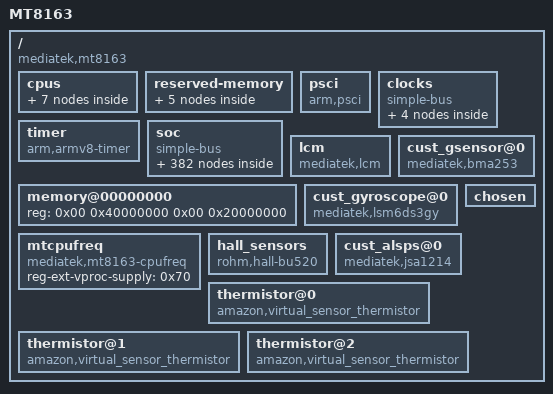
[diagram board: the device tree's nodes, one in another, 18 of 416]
/dts-v1/;

/ {
	model = "MT8163";
	compatible = "mediatek,mt8163";
	interrupt-parent = <0x01>;
	#address-cells = <0x02>;
	#size-cells = <0x02>;
	version = "hvt";

	cpus {
		#address-cells = <0x01>;
		#size-cells = <0x00>;

		cpu@0 {
			device_type = "cpu";
			compatible = "arm,cortex-a53";
			reg = <0x00>;
			enable-method = "mt-boot";
			cpu-idle-states = <0x02 0x02 0x03 0x03 0x03>;
			cpu-release-addr = <0x00 0x40000200>;
			clock-frequency = "M|m";
		};

		cpu@1 {
			device_type = "cpu";
			compatible = "arm,cortex-a53";
			reg = <0x01>;
			enable-method = "mt-boot";
			cpu-idle-states = <0x02 0x02 0x03 0x03 0x03>;
			cpu-release-addr = <0x00 0x40000200>;
			clock-frequency = "M|m";
		};

		cpu@2 {
			device_type = "cpu";
			compatible = "arm,cortex-a53";
			reg = <0x02>;
			enable-method = "mt-boot";
			cpu-idle-states = <0x02 0x02 0x03 0x03 0x03>;
			cpu-release-addr = <0x00 0x40000200>;
			clock-frequency = "M|m";
		};

		cpu@3 {
			device_type = "cpu";
			compatible = "arm,cortex-a53";
			reg = <0x03>;
			enable-method = "mt-boot";
			cpu-idle-states = <0x02 0x02 0x03 0x03 0x03>;
			cpu-release-addr = <0x00 0x40000200>;
			clock-frequency = "M|m";
		};

		idle-states {
			entry-method = "arm,psci";

			cpu-sleep-0-0 {
				compatible = "arm,idle-state";
				arm,psci-suspend-param = <0x10000>;
				entry-latency-us = <0x258>;
				exit-latency-us = <0x258>;
				min-residency-us = <0x4b0>;
				linux,phandle = <0x03>;
				phandle = <0x03>;
			};

			cluster-sleep-0 {
				compatible = "arm,idle-state";
				arm,psci-suspend-param = <0x2010000>;
				entry-latency-us = <0x320>;
				exit-latency-us = <0x3e8>;
				min-residency-us = <0x7d0>;
				linux,phandle = <0x02>;
				phandle = <0x02>;
			};
		};
	};

	reserved-memory {
		#address-cells = <0x02>;
		#size-cells = <0x02>;
		ranges;

		mdump-reserved-memory@4bd00000 {
			compatible = "amazon,mdump-reserve-memory";
			reg = <0x00 0x4bd00000 0x00 0x300000>;
		};

		atf-reserved-memory@43000000 {
			compatible = "mediatek,mt8163-atf-reserved-memory";
			no-map;
			reg = <0x00 0x43000000 0x00 0x30000>;
		};

		ram_console-reserved-memory@44400000 {
			compatible = "mediatek,ram_console";
			reg = <0x00 0x44400000 0x00 0x200000>;
		};

		consys-reserve-memory {
			compatible = "mediatek,consys-reserve-memory";
			no-map;
			size = <0x00 0x200000>;
			alignment = <0x00 0x200000>;
		};

		ll_log-reserved-memory@46600000 {
			compatible = "amazon,ll_log-reserved-memory";
			reg = <0x00 0x44600000 0x00 0x20000>;
		};
	};

	psci {
		compatible = "arm,psci";
		method = "smc";
		cpu_suspend = <0x84000001>;
		cpu_off = <0x84000002>;
		cpu_on = <0x84000003>;
		affinity_info = <0x84000004>;
	};

	clocks {
		#address-cells = <0x02>;
		#size-cells = <0x02>;
		compatible = "simple-bus";
		ranges;

		clk_null {
			compatible = "fixed-clock";
			#clock-cells = <0x00>;
			clock-frequency = <0x00>;
			linux,phandle = <0x3e>;
			phandle = <0x3e>;
		};

		clk26m {
			compatible = "fixed-clock";
			#clock-cells = <0x00>;
			clock-frequency = <0x18cba80>;
			linux,phandle = <0x33>;
			phandle = <0x33>;
		};

		clk32k {
			compatible = "fixed-clock";
			#clock-cells = <0x00>;
			clock-frequency = <0x7d00>;
		};

		dummy26m {
			compatible = "fixed-clock";
			clock-frequency = <0x18cba80>;
			#clock-cells = <0x00>;
		};
	};

	timer {
		compatible = "arm,armv8-timer";
		interrupt-parent = <0x04>;
		interrupts = <0x01 0x0d 0xf08 0x01 0x0e 0xf08 0x01 0x0b 0xf08 0x01 0x0a 0xf08>;
		clock-frequency = <0xc65d40>;
	};

	soc {
		#address-cells = <0x02>;
		#size-cells = <0x02>;
		compatible = "simple-bus";
		ranges;

		chipid@08000000 {
			compatible = "mediatek,mt8163-chipid";
			reg = <0x00 0x8000000 0x00 0x10>;
		};

		topckgen@10000000 {
			compatible = "mediatek,mt8163-topckgen";
			reg = <0x00 0x10000000 0x00 0x1000>;
			#clock-cells = <0x01>;
			linux,phandle = <0x06>;
			phandle = <0x06>;
		};

		infracfg@10001000 {
			compatible = "mediatek,mt8163-infracfg\0syscon";
			reg = <0x00 0x10001000 0x00 0x1000>;
			#clock-cells = <0x01>;
			#reset-cells = <0x01>;
			linux,phandle = <0x05>;
			phandle = <0x05>;
		};

		syscfg_pctl_a@10005000 {
			compatible = "mediatek,mt8163-pctl-a-syscfg\0syscon";
			reg = <0x00 0x10005000 0x00 0x1000>;
			linux,phandle = <0x07>;
			phandle = <0x07>;
		};

		toprgu@10007000 {
			compatible = "mediatek,mt8163-rgu";
			reg = <0x00 0x10007000 0x00 0x1000>;
			interrupts = <0x00 0x80 0x02>;
			#reset-cells = <0x01>;
		};

		apxgpt@10008000 {
			compatible = "mediatek,mt8163-apxgpt";
			reg = <0x00 0x10008000 0x00 0x1000>;
			interrupts = <0x00 0x98 0x08>;
			clocks = <0x05 0x06 0x05 0x46 0x06 0x60>;
			clock-names = "bus\0clk13m\0rtc_sel";
		};

		pinctrl@10005000 {
			compatible = "mediatek,mt8163-pinctrl";
			reg = <0x00 0x1000b000 0x00 0x1000>;
			mediatek,pctl-regmap = <0x07>;
			pins-are-numbered;
			gpio-controller;
			#gpio-cells = <0x02>;
			interrupt-controller;
			#interrupt-cells = <0x02>;
			interrupts = <0x00 0x99 0x04 0x00 0x9a 0x04 0x00 0x9b 0x04>;
			pinctrl-names = "default";
			pinctrl-0 = <0x08>;
			linux,phandle = <0x09>;
			phandle = <0x09>;

			spi1 {
				linux,phandle = <0x27>;
				phandle = <0x27>;

				pins_spi {
					pinmux = <0x3501 0x3601 0x3701 0x3801>;
					bias-disable;
					drive-strength = <0x08>;
				};
			};

			uart0gpiodefault {
				linux,phandle = <0x0b>;
				phandle = <0x0b>;
			};

			uart0_rx_set {
				linux,phandle = <0x0c>;
				phandle = <0x0c>;

				pins_cmd_dat {
					pinmux = <0x4f01>;
				};
			};

			uart0_rx_clear {
				linux,phandle = <0x0d>;
				phandle = <0x0d>;

				pins_cmd_dat {
					pinmux = <0x4f00>;
					slew-rate = <0x01>;
					output-high;
				};
			};

			uart0_tx_set {
				linux,phandle = <0x0e>;
				phandle = <0x0e>;

				pins_cmd_dat {
					pinmux = <0x5001>;
				};
			};

			uart0_tx_clear {
				linux,phandle = <0x0f>;
				phandle = <0x0f>;

				pins_cmd_dat {
					pinmux = <0x5000>;
					slew-rate = <0x01>;
					output-high;
				};
			};

			uart1gpiodefault {
				linux,phandle = <0x10>;
				phandle = <0x10>;
			};

			uart1_rx_set {
				linux,phandle = <0x11>;
				phandle = <0x11>;

				pins_cmd_dat {
					pinmux = <0x5101>;
				};
			};

			uart1_rx_clear {
				linux,phandle = <0x12>;
				phandle = <0x12>;

				pins_cmd_dat {
					pinmux = <0x5100>;
					slew-rate = <0x01>;
					output-high;
				};
			};

			uart1_tx_set {
				linux,phandle = <0x13>;
				phandle = <0x13>;

				pins_cmd_dat {
					pinmux = <0x5201>;
				};
			};

			uart1_tx_clear {
				linux,phandle = <0x14>;
				phandle = <0x14>;

				pins_cmd_dat {
					pinmux = <0x5200>;
					slew-rate = <0x01>;
					output-high;
				};
			};

			uart2gpiodefault {
				linux,phandle = <0x15>;
				phandle = <0x15>;
			};

			uart2_rx_set {
				linux,phandle = <0x16>;
				phandle = <0x16>;

				pins_cmd_dat {
					pinmux = <0xe01>;
				};
			};

			uart2_rx_clear {
				linux,phandle = <0x17>;
				phandle = <0x17>;

				pins_cmd_dat {
					pinmux = <0xe00>;
					slew-rate = <0x01>;
					output-high;
				};
			};

			uart2_tx_set {
				linux,phandle = <0x18>;
				phandle = <0x18>;

				pins_cmd_dat {
					pins = <0xf01>;
				};
			};

			uart2_tx_clear {
				linux,phandle = <0x19>;
				phandle = <0x19>;

				pins_cmd_dat {
					pinmux = <0xf00>;
					slew-rate = <0x01>;
					output-high;
				};
			};

			uart3gpiodefault {
				linux,phandle = <0x1a>;
				phandle = <0x1a>;
			};

			uart3_rx_set {
				linux,phandle = <0x1b>;
				phandle = <0x1b>;

				pins_cmd_dat {
					pinmux = <0x1001>;
				};
			};

			uart3_rx_clear {
				linux,phandle = <0x1c>;
				phandle = <0x1c>;

				pins_cmd_dat {
					pinmux = <0x1000>;
					slew-rate = <0x01>;
					output-high;
				};
			};

			uart3_tx_set {
				linux,phandle = <0x1d>;
				phandle = <0x1d>;

				pins_cmd_dat {
					pinmux = <0x1101>;
				};
			};

			uart3_tx_clear {
				linux,phandle = <0x1e>;
				phandle = <0x1e>;

				pins_cmd_dat {
					pinmux = <0x1100>;
					slew-rate = <0x01>;
					output-high;
				};
			};

			pinconf_default {
				linux,phandle = <0x08>;
				phandle = <0x08>;
			};

			eint4default {
				linux,phandle = <0x60>;
				phandle = <0x60>;
			};

			eint4 {
				linux,phandle = <0x61>;
				phandle = <0x61>;

				pins_cmd_dat {
					pins = <0x1a00>;
					input-enable;
					bias-pull-down;
				};
			};

			bq24297_int_pin {
				linux,phandle = <0x26>;
				phandle = <0x26>;

				pins_cmd_dat {
					pinmux = <0x1700>;
					input-enable;
					bias-pull-up;
				};
			};

			bq24297_chg_en_pin {
				linux,phandle = <0x25>;
				phandle = <0x25>;

				pins_cmd_dat {
					pins = <0x1600>;
					slew-rate = <0x01>;
					bias-disable;
					output-low;
				};
			};

			alspspincfg {
				linux,phandle = <0x6a>;
				phandle = <0x6a>;

				pins_cmd_dat {
					pins = <0x3400>;
					slew-rate = <0x00>;
					bias-pull-up = <0x00>;
				};
			};

			alspsdefaultcfg {
				linux,phandle = <0x69>;
				phandle = <0x69>;
			};

			audiodefault {
				linux,phandle = <0x35>;
				phandle = <0x35>;
			};

			audexamphigh {
				linux,phandle = <0x3a>;
				phandle = <0x3a>;

				pins_cmd_dat {
					pins = <0x1c00>;
					slew-rate = <0x01>;
					output-high;
				};
			};

			audexamplow {
				linux,phandle = <0x3b>;
				phandle = <0x3b>;

				pins_cmd_dat {
					pins = <0x1c00>;
					slew-rate = <0x01>;
					output-low;
				};
			};

			audhpamphigh {
				linux,phandle = <0x3c>;
				phandle = <0x3c>;

				pins_cmd_dat {
					pins = <0x2c00>;
					slew-rate = <0x01>;
					output-high;
				};
			};

			audhpamplow {
				linux,phandle = <0x3d>;
				phandle = <0x3d>;

				pins_cmd_dat {
					pins = <0x2c00>;
					slew-rate = <0x01>;
					output-low;
				};
			};

			audFSA8409off {
				linux,phandle = <0x62>;
				phandle = <0x62>;

				pins_cmd_dat {
					pins = <0x1b00>;
					slew-rate = <0x01>;
					output-low;
				};
			};

			audFSA8409on {
				linux,phandle = <0x63>;
				phandle = <0x63>;

				pins_cmd_dat {
					pins = <0x1b00>;
					slew-rate = <0x01>;
					output-high;
				};
			};

			audi2s1mode0 {
				linux,phandle = <0x38>;
				phandle = <0x38>;

				pins_cmd0_dat {
					pins = <0x2e00>;
				};

				pins_cmd1_dat {
					pins = <0x2f00>;
				};

				pins_cmd2_dat {
					pins = <0x3000>;
				};
			};

			audi2s1mode1 {
				linux,phandle = <0x39>;
				phandle = <0x39>;

				pins_cmd0_dat {
					pins = <0x2e02>;
				};

				pins_cmd1_dat {
					pins = <0x2f02>;
				};

				pins_cmd2_dat {
					pins = <0x3002>;
				};
			};

			pmicclkmode0 {
				linux,phandle = <0x36>;
				phandle = <0x36>;

				pins_cmd0_dat {
					pins = <0x700>;
				};

				pins_cmd1_dat {
					pins = <0x800>;
				};

				pins_cmd2_dat {
					pins = <0x900>;
				};
			};

			pmicclkmode1 {
				linux,phandle = <0x37>;
				phandle = <0x37>;

				pins_cmd0_dat {
					pins = <0x701>;
				};

				pins_cmd1_dat {
					pins = <0x801>;
				};

				pins_cmd2_dat {
					pins = <0x901>;
				};
			};

			cam0@0 {
				linux,phandle = <0x4d>;
				phandle = <0x4d>;

				pins_cmd_dat {
					pins = <0x3500>;
					slew-rate = <0x01>;
					output-low;
				};
			};

			cam0@1 {
				linux,phandle = <0x4e>;
				phandle = <0x4e>;

				pins_cmd_dat {
					pins = <0x3500>;
					slew-rate = <0x01>;
					output-high;
				};
			};

			cam0@2 {
				linux,phandle = <0x4f>;
				phandle = <0x4f>;

				pins_cmd_dat {
					pins = <0x3800>;
					slew-rate = <0x01>;
					output-low;
				};
			};

			cam0@3 {
				linux,phandle = <0x50>;
				phandle = <0x50>;

				pins_cmd_dat {
					pins = <0x3800>;
					slew-rate = <0x01>;
					output-high;
				};
			};

			cam1@0 {
				linux,phandle = <0x51>;
				phandle = <0x51>;

				pins_cmd_dat {
					pins = <0x3700>;
					slew-rate = <0x01>;
					output-low;
				};
			};

			cam1@1 {
				linux,phandle = <0x52>;
				phandle = <0x52>;

				pins_cmd_dat {
					pins = <0x3700>;
					slew-rate = <0x01>;
					output-high;
				};
			};

			cam1@2 {
				linux,phandle = <0x53>;
				phandle = <0x53>;

				pins_cmd_dat {
					pins = <0x3600>;
					slew-rate = <0x01>;
					output-low;
				};
			};

			cam1@3 {
				linux,phandle = <0x54>;
				phandle = <0x54>;

				pins_cmd_dat {
					pins = <0x3600>;
					slew-rate = <0x01>;
					output-high;
				};
			};

			camdefault {
				linux,phandle = <0x4c>;
				phandle = <0x4c>;

				pins_cmd0_dat {
					pins = <0x7701>;
				};

				pins_cmd1_dat {
					pins = <0x6b02>;
				};

				pins_cmd2_dat {
					pins = <0x6c02>;
				};

				pins_cmd3_dat {
					pins = <0x6d02>;
				};

				pins_cmd4_dat {
					pins = <0x6e02>;
				};

				pins_cmd5_dat {
					pins = <0x6f02>;
				};

				pins_cmd6_dat {
					pins = <0x7002>;
				};

				pins_cmd7_dat {
					pins = <0x7102>;
				};

				pins_cmd8_dat {
					pins = <0x7202>;
				};

				pins_cmd9_dat {
					pins = <0x7302>;
				};

				pins_cmd10_dat {
					pins = <0x7402>;
				};

				pins_cmd11_dat {
					pins = <0x7801>;
				};
			};

			default {
				linux,phandle = <0x57>;
				phandle = <0x57>;
			};

			eint0default {
				linux,phandle = <0x65>;
				phandle = <0x65>;

				pins_cmd_dat {
					pins = <0x2300>;
					slew-rate = <0x00>;
					bias-disable;
				};
			};

			eint@0 {
				linux,phandle = <0x22>;
				phandle = <0x22>;

				pins_cmd_dat {
					pins = <0x2300>;
					slew-rate = <0x00>;
					bias-disable;
				};
			};

			eintoutput0 {
				linux,phandle = <0x21>;
				phandle = <0x21>;

				pins_cmd_dat {
					pins = <0x2300>;
					slew-rate = <0x01>;
					output-low;
				};
			};

			eintoutput1 {
				linux,phandle = <0x66>;
				phandle = <0x66>;

				pins_cmd_dat {
					pins = <0x2300>;
					slew-rate = <0x01>;
					output-high;
				};
			};

			rstoutput0 {
				linux,phandle = <0x67>;
				phandle = <0x67>;

				pins_cmd_dat {
					pins = <0x2e00>;
					slew-rate = <0x01>;
					output-low;
				};
			};

			rstoutput1 {
				linux,phandle = <0x68>;
				phandle = <0x68>;

				pins_cmd_dat {
					pins = <0x2e00>;
					slew-rate = <0x01>;
					output-high;
				};
			};

			iddig_irq_init {
				linux,phandle = <0x2a>;
				phandle = <0x2a>;

				pins_cmd_dat {
					pins = <0x2600>;
					bias-pull-up;
				};
			};

			iddig_irq_low {
				linux,phandle = <0x2b>;
				phandle = <0x2b>;

				pins_cmd_dat {
					pins = <0x2600>;
					bias-pull-down;
				};
			};

			iddig_irq_high {
				linux,phandle = <0x2c>;
				phandle = <0x2c>;

				pins_cmd_dat {
					pins = <0x2600>;
					bias-pull-up;
				};
			};

			drvvbus_init {
				linux,phandle = <0x2d>;
				phandle = <0x2d>;

				pins_cmd_dat {
					pins = <0x1e00>;
					slew-rate = <0x01>;
					bias-pull-up = <0x00>;
				};
			};

			drvvbus_low {
				linux,phandle = <0x2e>;
				phandle = <0x2e>;

				pins_cmd_dat {
					pins = <0x1e00>;
					slew-rate = <0x01>;
					output-low;
				};
			};

			drvvbus_high {
				linux,phandle = <0x2f>;
				phandle = <0x2f>;

				pins_cmd_dat {
					pins = <0x1e00>;
					slew-rate = <0x01>;
					output-high;
				};
			};

			otg5ven_init {
				linux,phandle = <0x30>;
				phandle = <0x30>;

				pins_cmd_dat {
					pins = <0x1d00>;
					slew-rate = <0x01>;
					bias-pull-up = <0x00>;
				};
			};

			otg5ven_low {
				linux,phandle = <0x31>;
				phandle = <0x31>;

				pins_cmd_dat {
					pins = <0x1d00>;
					slew-rate = <0x01>;
					output-low;
				};
			};

			otg5ven_high {
				linux,phandle = <0x32>;
				phandle = <0x32>;

				pins_cmd_dat {
					pins = <0x1d00>;
					slew-rate = <0x01>;
					output-high;
				};
			};

			gpslna@0 {
				linux,phandle = <0x58>;
				phandle = <0x58>;

				pins_cmd_dat {
					pinmux = <0x600>;
					slew-rate = <0x00>;
					bias-disable;
					output-low;
				};
			};

			gpslna@1 {
				linux,phandle = <0x59>;
				phandle = <0x59>;

				pins_cmd_dat {
					pinmux = <0x600>;
					slew-rate = <0x01>;
					output-high;
				};
			};

			gpslna@2 {
				linux,phandle = <0x5a>;
				phandle = <0x5a>;

				pins_cmd_dat {
					pinmux = <0x600>;
					slew-rate = <0x01>;
					output-low;
				};
			};

			wifireset@0 {
				linux,phandle = <0x5b>;
				phandle = <0x5b>;

				pins_reset_dat {
					pinmux = <0x3c01 0x3f01 0x4001 0x4101>;
					input-enable;
					bias-pull-up;
				};
			};

			i2c0@0 {
				linux,phandle = <0x1f>;
				phandle = <0x1f>;

				pins1 {
					pinmux = <0x4b01 0x4c01>;
					bias-disable;
				};
			};

			i2c1@0 {
				linux,phandle = <0x23>;
				phandle = <0x23>;

				pins1 {
					pinmux = <0x3901 0x3a01>;
					bias-disable;
				};
			};

			i2c2@0 {
				linux,phandle = <0x24>;
				phandle = <0x24>;

				pins1 {
					pinmux = <0x4d01 0x4e01>;
					bias-disable;
				};
			};

			lcm_gpio@43_high {
				linux,phandle = <0x6b>;
				phandle = <0x6b>;

				pins_cmd_dat {
					pins = <0x2b00>;
					slew-rate = <0x01>;
					output-high;
				};
			};

			lcm_gpio@43_low {
				linux,phandle = <0x6c>;
				phandle = <0x6c>;

				pins_cmd_dat {
					pins = <0x2b00>;
					slew-rate = <0x01>;
					output-low;
				};
			};

			lcm_gpio@83_high {
				linux,phandle = <0x6d>;
				phandle = <0x6d>;

				pins_cmd_dat {
					pins = <0x5300>;
					slew-rate = <0x01>;
					output-high;
				};
			};

			lcm_gpio@83_low {
				linux,phandle = <0x6e>;
				phandle = <0x6e>;

				pins_cmd_dat {
					pins = <0x5300>;
					slew-rate = <0x01>;
					output-low;
				};
			};

			mmc0default {
				linux,phandle = <0x3f>;
				phandle = <0x3f>;

				pins_cmd_dat {
					pinmux = <0x8901 0x8801 0x8701 0x8601 0x8201 0x8101 0x8001 0x7f01 0x8401>;
					input-enable;
					bias-pull-up;
				};

				pins_clk {
					pinmux = <0x8501>;
					bias-pull-down;
				};

				pins_rst {
					pinmux = <0x8301>;
					bias-pull-up;
				};
			};

			mmc0@0 {
				linux,phandle = <0x40>;
				phandle = <0x40>;

				pins_cmd_dat {
					pinmux = <0x8901 0x8801 0x8701 0x8601 0x8201 0x8101 0x8001 0x7f01 0x8401>;
					input-enable;
					drive-strength = <0x06>;
					bias-pull-up = <0x65>;
				};

				pins_clk {
					pinmux = <0x8501>;
					drive-strength = <0x06>;
					bias-pull-down = <0x65>;
				};

				pins_rst {
					pinmux = <0x8301>;
					bias-pull-up;
				};
			};

			mmc1default {
				linux,phandle = <0x43>;
				phandle = <0x43>;

				pins_cmd_dat {
					pinmux = <0x7b01 0x7c01 0x7d01 0x7e01 0x7901>;
					input-enable;
					drive-strength = <0x06>;
					bias-pull-up = <0x65>;
				};

				pins_clk {
					pinmux = <0x7a01>;
					bias-pull-down = <0x66>;
					drive-strength = <0x06>;
				};

				pins_insert {
					pinmux = <0x3100>;
					bias-pull-up;
				};
			};

			mmc1@0 {
				linux,phandle = <0x44>;
				phandle = <0x44>;

				pins_cmd_dat {
					pinmux = <0x7b01 0x7c01 0x7d01 0x7e01 0x7901>;
					input-enable;
					drive-strength = <0x08>;
					bias-pull-up = <0x66>;
				};

				pins_clk {
					pinmux = <0x7a01>;
					drive-strength = <0x08>;
					bias-pull-down = <0x66>;
				};
			};
		};

		dramco@10004000 {
			compatible = "mediatek,mt8163-dramco\0mediatek,dramco";
			reg = <0x00 0x10004000 0x00 0x1000>;
		};

		scpsys@10006000 {
			compatible = "mediatek,mt8163-scpsys\0syscon";
			#power-domain-cells = <0x01>;
			reg = <0x00 0x10006000 0x00 0x1000>;
			interrupts = <0x00 0xa3 0x08 0x00 0xa4 0x08 0x00 0xa5 0x08 0x00 0xa6 0x08 0x00 0xa7 0x08 0x00 0xa8 0x08 0x00 0xa9 0x08 0x00 0xaa 0x08>;
			infracfg = <0x05>;
			clocks = <0x06 0x46 0x06 0x43>;
			clock-names = "mfg\0mm";
			linux,phandle = <0x34>;
			phandle = <0x34>;
		};

		hacc@1000a000 {
			compatible = "mediatek,hacc";
			reg = <0x00 0x1000a000 0x00 0x1000>;
			clocks = <0x05 0x05>;
			clock-names = "main";
		};

		apmixedsys@1000c000 {
			compatible = "mediatek,mt8163-apmixedsys";
			reg = <0x00 0x1000c000 0x00 0x1000>;
			#clock-cells = <0x01>;
			linux,phandle = <0x28>;
			phandle = <0x28>;
		};

		fhctl@1000cf00 {
			compatible = "mediatek,mt8163-fhctl";
			reg = <0x00 0x1000cf00 0x00 0x100>;
		};

		pwrap@1000d000 {
			compatible = "mediatek,mt8163-pwrap";
			reg = <0x00 0x1000d000 0x00 0x1000>;
			reg-names = "pwrap-base";
			interrupts = <0x00 0xa1 0x04>;
			clocks = <0x06 0x51 0x05 0x01>;
			clock-names = "spi\0pwrap";

			mt6323 {
				compatible = "mediatek,mt6323";

				pmicmt6323 {
					compatible = "mediatek,mt6323-pmic";
					interrupt-parent = <0x09>;
					interrupts = <0x18 0x04>;
					log-dump-wait-time = <0x1770>;
				};

				regulators {
					compatible = "mediatek,mt6323-regulator";

					buck_vproc {
						regulator-name = "vproc";
						regulator-min-microvolt = <0xaae60>;
						regulator-max-microvolt = <0x149970>;
						regulator-ramp-delay = <0x30d4>;
						regulator-always-on;
						regulator-boot-on;
					};

					buck_vsys {
						regulator-name = "vsys";
						regulator-min-microvolt = <0x155cc0>;
						regulator-max-microvolt = <0x2d95ec>;
						regulator-ramp-delay = <0x61a8>;
						regulator-always-on;
						regulator-boot-on;
					};

					buck_vpa {
						regulator-name = "vpa";
						regulator-min-microvolt = <0x7a120>;
						regulator-max-microvolt = <0x37b1d0>;
					};

					ldo_vtcxo {
						regulator-name = "vtcxo";
						regulator-min-microvolt = <0x2ab980>;
						regulator-max-microvolt = <0x2ab980>;
						regulator-enable-ramp-delay = <0x5a>;
						regulator-always-on;
						regulator-boot-on;
					};

					ldo_vcn28 {
						regulator-name = "vcn28";
						regulator-min-microvolt = <0x2ab980>;
						regulator-max-microvolt = <0x2ab980>;
						regulator-enable-ramp-delay = <0xb9>;
						linux,phandle = <0x5d>;
						phandle = <0x5d>;
					};

					ldo_vcn33_bt {
						regulator-name = "vcn33_bt";
						regulator-min-microvolt = <0x325aa0>;
						regulator-max-microvolt = <0x36ee80>;
						regulator-enable-ramp-delay = <0xb9>;
						linux,phandle = <0x5e>;
						phandle = <0x5e>;
					};

					ldo_vcn33_wifi {
						regulator-name = "vcn33_wifi";
						regulator-min-microvolt = <0x325aa0>;
						regulator-max-microvolt = <0x36ee80>;
						regulator-enable-ramp-delay = <0xb9>;
						linux,phandle = <0x5f>;
						phandle = <0x5f>;
					};

					ldo_va {
						regulator-name = "va";
						regulator-min-microvolt = <0x2ab980>;
						regulator-max-microvolt = <0x2ab980>;
						regulator-enable-ramp-delay = <0xd8>;
						regulator-always-on;
						regulator-boot-on;
					};

					ldo_vcama {
						regulator-name = "vcama";
						regulator-min-microvolt = <0x16e360>;
						regulator-max-microvolt = <0x2ab980>;
						regulator-enable-ramp-delay = <0xd8>;
						linux,phandle = <0x49>;
						phandle = <0x49>;
					};

					ldo_vio28 {
						regulator-name = "vio28";
						regulator-min-microvolt = <0x2ab980>;
						regulator-max-microvolt = <0x2ab980>;
						regulator-enable-ramp-delay = <0xd8>;
						regulator-always-on;
						regulator-boot-on;
					};

					ldo_vusb {
						regulator-name = "vusb";
						regulator-min-microvolt = <0x325aa0>;
						regulator-max-microvolt = <0x325aa0>;
						regulator-enable-ramp-delay = <0xd8>;
						regulator-boot-on;
						linux,phandle = <0x29>;
						phandle = <0x29>;
					};

					ldo_vmc {
						regulator-name = "vmc";
						regulator-min-microvolt = <0x1b7740>;
						regulator-max-microvolt = <0x325aa0>;
						regulator-enable-ramp-delay = <0x24>;
						regulator-boot-on;
						linux,phandle = <0x46>;
						phandle = <0x46>;
					};

					ldo_vmch {
						regulator-name = "vmch";
						regulator-min-microvolt = <0x2dc6c0>;
						regulator-max-microvolt = <0x325aa0>;
						regulator-enable-ramp-delay = <0x24>;
						regulator-boot-on;
						linux,phandle = <0x45>;
						phandle = <0x45>;
					};

					ldo_vemc3v3 {
						regulator-name = "vemc3v3";
						regulator-min-microvolt = <0x2dc6c0>;
						regulator-max-microvolt = <0x325aa0>;
						regulator-enable-ramp-delay = <0x24>;
						regulator-boot-on;
						linux,phandle = <0x41>;
						phandle = <0x41>;
					};

					ldo_vgp1 {
						regulator-name = "vgp1";
						regulator-min-microvolt = <0x124f80>;
						regulator-max-microvolt = <0x325aa0>;
						regulator-enable-ramp-delay = <0xd8>;
					};

					ldo_vgp2 {
						regulator-name = "vgp2";
						regulator-min-microvolt = <0x124f80>;
						regulator-max-microvolt = <0x2dc6c0>;
						regulator-enable-ramp-delay = <0xd8>;
						linux,phandle = <0x20>;
						phandle = <0x20>;
					};

					ldo_vgp3 {
						regulator-name = "vgp3";
						regulator-min-microvolt = <0x124f80>;
						regulator-max-microvolt = <0x1b7740>;
						regulator-enable-ramp-delay = <0xd8>;
						regulator-boot-on;
						linux,phandle = <0x6f>;
						phandle = <0x6f>;
					};

					ldo_vcn18 {
						regulator-name = "vcn18";
						regulator-min-microvolt = <0x1b7740>;
						regulator-max-microvolt = <0x1b7740>;
						regulator-enable-ramp-delay = <0xd8>;
						linux,phandle = <0x5c>;
						phandle = <0x5c>;
					};

					ldo_vsim1 {
						regulator-name = "vsim1";
						regulator-min-microvolt = <0x1b7740>;
						regulator-max-microvolt = <0x2dc6c0>;
						regulator-enable-ramp-delay = <0xd8>;
					};

					ldo_vsim2 {
						regulator-name = "vsim2";
						regulator-min-microvolt = <0x1b7740>;
						regulator-max-microvolt = <0x2dc6c0>;
						regulator-enable-ramp-delay = <0xd8>;
					};

					ldo_vrtc {
						regulator-name = "vrtc";
						regulator-min-microvolt = <0x2ab980>;
						regulator-max-microvolt = <0x2ab980>;
						regulator-always-on;
						regulator-boot-on;
					};

					ldo_vcamaf {
						regulator-name = "vcamaf";
						regulator-min-microvolt = <0x124f80>;
						regulator-max-microvolt = <0x325aa0>;
						regulator-enable-ramp-delay = <0xd8>;
						linux,phandle = <0x64>;
						phandle = <0x64>;
					};

					ldo_vibr {
						regulator-name = "vibr";
						regulator-min-microvolt = <0x124f80>;
						regulator-max-microvolt = <0x325aa0>;
						regulator-enable-ramp-delay = <0x24>;
					};

					ldo_vrf18 {
						regulator-name = "vrf18";
						regulator-min-microvolt = <0x1bd8e8>;
						regulator-max-microvolt = <0x1bd8e8>;
						regulator-enable-ramp-delay = <0xbb>;
						regulator-boot-on;
					};

					ldo_vm {
						regulator-name = "vm";
						regulator-min-microvolt = <0x124f80>;
						regulator-max-microvolt = <0x1b7740>;
						regulator-enable-ramp-delay = <0xd8>;
						regulator-always-on;
						regulator-boot-on;
					};

					ldo_vio18 {
						regulator-name = "vio18";
						regulator-min-microvolt = <0x1b7740>;
						regulator-max-microvolt = <0x1b7740>;
						regulator-enable-ramp-delay = <0xd8>;
						regulator-always-on;
						regulator-boot-on;
						linux,phandle = <0x42>;
						phandle = <0x42>;
					};

					ldo_vcamd {
						regulator-name = "vcamd";
						regulator-min-microvolt = <0x124f80>;
						regulator-max-microvolt = <0x1b7740>;
						regulator-enable-ramp-delay = <0xd8>;
						linux,phandle = <0x4a>;
						phandle = <0x4a>;
					};

					ldo_vcamio {
						regulator-name = "vcamio";
						regulator-min-microvolt = <0x1b7740>;
						regulator-max-microvolt = <0x1b7740>;
						regulator-enable-ramp-delay = <0xd8>;
						linux,phandle = <0x4b>;
						phandle = <0x4b>;
					};
				};
			};
		};

		devapc_ao@1000e000 {
			compatible = "mediatek,mt8163-devapc_ao";
			reg = <0x00 0x1000e000 0x00 0x1000>;
		};

		ddrphy@1000f000 {
			compatible = "mediatek,mt8163-ddrphy\0mediatek,ddrphy";
			reg = <0x00 0x1000f000 0x00 0x1000>;
			clocks = <0x05 0x36>;
			clock-names = "dramc_f26m";
		};

		keypad@10010000 {
			compatible = "mediatek,mt8163-keypad";
			reg = <0x00 0x10010000 0x00 0x1000>;
			interrupts = <0x00 0xa2 0x02>;
			mediatek,kpd-key-debounce = <0x400>;
			mediatek,kpd-sw-pwrkey = <0x74>;
			mediatek,kpd-hw-pwrkey = <0x08>;
			mediatek,kpd-sw-rstkey = <0x72>;
			mediatek,kpd-hw-rstkey = <0x11>;
			mediatek,kpd-use-extend-type = <0x00>;
			mediatek,kpd-hw-map-num = <0x48>;
			mediatek,kpd-hw-init-map = <0x73 0x00 0x00 0x00 0x00 0x00 0x00 0x00 0x00 0x00 0x00 0x00 0x00 0x00 0x00 0x00 0x00 0x00 0x00 0x00 0x00 0x00 0x00 0x00 0x00 0x00 0x00 0x00 0x00 0x00 0x00 0x00 0x00 0x00 0x00 0x00 0x00 0x00 0x00 0x00 0x00 0x00 0x00 0x00 0x00 0x00 0x00 0x00 0x00 0x00 0x00 0x00 0x00 0x00 0x00 0x00 0x00 0x00 0x00 0x00 0x00 0x00 0x00 0x00 0x00 0x00 0x00 0x00 0x00 0x00 0x00 0x00>;
			mediatek,kpd-pwrkey-eint-gpio = <0x00>;
			mediatek,kpd-pwkey-gpio-din = <0x00>;
			mediatek,kpd-hw-dl-key0 = <0x00>;
			mediatek,kpd-hw-dl-key1 = <0x11>;
			mediatek,kpd-hw-dl-key2 = <0x08>;
			mediatek,kpd-hw-recovery-key = <0x00>;
			mediatek,kpd-hw-factory-key = <0x11>;
		};

		md32@10020000 {
			compatible = "mediatek,mt8163-md32";
			reg = <0x00 0x10020000 0x00 0x38000 0x00 0x10058000 0x00 0x400 0x00 0x10059000 0x00 0x400>;
			interrupts = <0x00 0xae 0x04>;
			clocks = <0x05 0x04>;
			clock-names = "sys";
			status = "okay";
		};

		mcucfg@10200000 {
			compatible = "mediatek,mt8173-mcucfg\0syscon";
			reg = <0x00 0x10200000 0x00 0x1000>;
		};

		cpuxgpt@10200000 {
			compatible = "mediatek,mt8163-cpuxgpt";
			interrupts = <0x00 0x40 0x04 0x00 0x41 0x04 0x00 0x42 0x04 0x00 0x43 0x04>;
		};

		lastpc@10200000 {
			compatible = "mediatek,mt8163-mcucfg";
			reg = <0x00 0x10200000 0x00 0x200>;
		};

		intpol-controller@10200620 {
			compatible = "mediatek,mt8163-sysirq\0mediatek,mt6577-sysirq";
			interrupt-controller;
			#interrupt-cells = <0x03>;
			interrupt-parent = <0x04>;
			reg = <0x00 0x10200620 0x00 0x20>;
			linux,phandle = <0x01>;
			phandle = <0x01>;
		};

		emi@10203000 {
			compatible = "mediatek,mt8163-emi\0mediatek,emi";
			reg = <0x00 0x10203000 0x00 0x1000>;
			interrupts = <0x00 0x85 0x04>;
		};

		sys_cirq@10204000 {
			compatible = "mediatek,mt8163-sys_cirq\0mediatek,mt6735-sys_cirq";
			reg = <0x00 0x10204000 0x00 0x1000>;
			interrupts = <0x00 0xf0 0x08>;
			mediatek,cirq_num = <0xa9>;
			mediatek,spi_start_offset = <0x48>;
		};

		m4u@10205000 {
			cell-index = <0x00>;
			compatible = "mediatek,mt8163-m4u";
			reg = <0x00 0x10205000 0x00 0x1000>;
			interrupts = <0x00 0x93 0x08>;
		};

		devapc@10207000 {
			compatible = "mediatek,mt8163-devapc";
			reg = <0x00 0x10207000 0x00 0x1000>;
			interrupts = <0x00 0x85 0x08>;
			clocks = <0x05 0x2b>;
			clock-names = "main";
		};

		systracker@10208000 {
			compatible = "mediatek,bus_dbg-v1";
			reg = <0x00 0x10208000 0x00 0x1000>;
			interrupts = <0x00 0x84 0x08>;
		};

		dramc_nao@1020e000 {
			compatible = "mediatek,mt8163-dramc_nao\0mediatek,dramc_nao";
			reg = <0x00 0x1020e000 0x00 0x1000>;
		};

		gcpu@10210000 {
			compatible = "mediatek,mt8163-gcpu";
			reg = <0x00 0x10210000 0x00 0x1000>;
			clocks = <0x05 0x20>;
			clock-names = "main";
		};

		gce@10212000 {
			compatible = "mediatek,mt8163-gce";
			reg = <0x00 0x10212000 0x00 0x1000>;
			interrupts = <0x00 0x8f 0x08 0x00 0x90 0x08>;
			clocks = <0x05 0x09 0x0a 0x00 0x0a 0x01 0x0a 0x02 0x0a 0x03 0x0a 0x04 0x0a 0x05 0x0a 0x06 0x0a 0x08 0x0a 0x07>;
			clock-names = "MT_CG_INFRA_GCE\0MT_CG_DISP0_SMI_COMMON\0MT_CG_DISP0_SMI_LARB0\0MT_CG_DISP0_CAM_MDP\0MT_CG_DISP0_MDP_RDMA0\0MT_CG_DISP0_MDP_RSZ0\0MT_CG_DISP0_MDP_RSZ1\0MT_CG_DISP0_MDP_TDSHP0\0MT_CG_DISP0_MDP_WROT0\0MT_CG_DISP0_MDP_WDMA";
		};

		perisys_iommu@10214000 {
			cell-index = <0x01>;
			compatible = "mediatek,mt8163-perisys_iommu";
			reg = <0x00 0x10214000 0x00 0x1000>;
			interrupts = <0x00 0x91 0x08>;
		};

		interrupt-controller@10221000 {
			compatible = "arm,gic-400";
			interrupt-controller;
			#interrupt-cells = <0x03>;
			interrupt-parent = <0x04>;
			reg = <0x00 0x10221000 0x00 0x1000 0x00 0x10222000 0x00 0x1000 0x00 0x10224000 0x00 0x2000 0x00 0x10226000 0x00 0x2000>;
			interrupts = <0x01 0x09 0xf04>;
			linux,phandle = <0x04>;
			phandle = <0x04>;
		};

		btif_tx@11000700 {
			compatible = "mediatek,btif_tx";
			reg = <0x00 0x11000700 0x00 0x80>;
			interrupts = <0x00 0x6e 0x08>;
		};

		btif_rx@11000780 {
			compatible = "mediatek,btif_rx";
			reg = <0x00 0x11000780 0x00 0x80>;
			interrupts = <0x00 0x6f 0x08>;
		};

		auxadc@11001000 {
			compatible = "mediatek,mt8163-auxadc\0mediatek,mt6735-auxadc";
			reg = <0x00 0x11001000 0x00 0x1000>;
			interrupts = <0x00 0x4c 0x02>;
			clocks = <0x05 0x21>;
			clock-names = "auxadc-main";
			status = "okay";
		};

		uart0@11002000 {
			cell-index = <0x00>;
			compatible = "mediatek,mt8163-uart";
			reg = <0x00 0x11002000 0x00 0x1000 0x00 0x11000300 0x00 0x1000 0x00 0x11000380 0x00 0x80>;
			interrupts = <0x00 0x5b 0x08 0x00 0x66 0x08 0x00 0x67 0x08>;
			clock-frequency = <0x18cba80>;
			clock-div = <0x01>;
			clocks = <0x05 0x13 0x05 0x29>;
			clock-names = "uart0-main\0uart-apdma";
			pinctrl-names = "uart0_gpio_default\0uart0_rx_set\0uart0_rx_clear\0uart0_tx_set\0uart0_tx_clear";
			pinctrl-0 = <0x0b>;
			pinctrl-1 = <0x0c>;
			pinctrl-2 = <0x0d>;
			pinctrl-3 = <0x0e>;
			pinctrl-4 = <0x0f>;
			rx_gpios = <0x09 0x4f 0x00>;
			tx_gpios = <0x09 0x50 0x00>;
			status = "okay";
		};

		uart1@11003000 {
			cell-index = <0x01>;
			compatible = "mediatek,mt8163-uart";
			reg = <0x00 0x11003000 0x00 0x1000 0x00 0x11000400 0x00 0x80 0x00 0x11000480 0x00 0x80>;
			interrupts = <0x00 0x5c 0x08 0x00 0x68 0x08 0x00 0x69 0x08>;
			clock-frequency = <0x18cba80>;
			clock-div = <0x01>;
			clocks = <0x05 0x14>;
			clock-names = "uart1-main";
			pinctrl-names = "uart1_gpio_default\0uart1_rx_set\0uart1_rx_clear\0uart1_tx_set\0uart1_tx_clear";
			pinctrl-0 = <0x10>;
			pinctrl-1 = <0x11>;
			pinctrl-2 = <0x12>;
			pinctrl-3 = <0x13>;
			pinctrl-4 = <0x14>;
			rx_gpios = <0x09 0x51 0x00>;
			tx_gpios = <0x09 0x52 0x00>;
			status = "disable";
		};

		uart2@11004000 {
			cell-index = <0x02>;
			compatible = "mediatek,mt8163-uart";
			reg = <0x00 0x11004000 0x00 0x1000 0x00 0x11000500 0x00 0x80 0x00 0x11000580 0x00 0x80>;
			interrupts = <0x00 0x5d 0x08 0x00 0x6a 0x08 0x00 0x6b 0x08>;
			clock-frequency = <0x18cba80>;
			clock-div = <0x01>;
			clocks = <0x05 0x15>;
			clock-names = "uart2-main";
			pinctrl-names = "uart2_gpio_default\0uart2_rx_set\0uart2_rx_clear\0uart2_tx_set\0uart2_tx_clear";
			pinctrl-0 = <0x15>;
			pinctrl-1 = <0x16>;
			pinctrl-2 = <0x17>;
			pinctrl-3 = <0x18>;
			pinctrl-4 = <0x19>;
			rx_gpios = <0x09 0x0e 0x00>;
			tx_gpios = <0x09 0x0f 0x00>;
			status = "disable";
		};

		uart3@11005000 {
			cell-index = <0x03>;
			compatible = "mediatek,mt8163-uart";
			reg = <0x00 0x11005000 0x00 0x1000 0x00 0x11000600 0x00 0x80 0x00 0x11000680 0x00 0x80>;
			interrupts = <0x00 0x5e 0x08 0x00 0x6c 0x08 0x00 0x6d 0x08>;
			clock-frequency = <0x18cba80>;
			clock-div = <0x01>;
			clocks = <0x05 0x16>;
			clock-names = "uart3-main";
			pinctrl-names = "uart3_gpio_default\0uart3_rx_set\0uart3_rx_clear\0uart3_tx_set\0uart3_tx_clear";
			pinctrl-0 = <0x1a>;
			pinctrl-1 = <0x1b>;
			pinctrl-2 = <0x1c>;
			pinctrl-3 = <0x1d>;
			pinctrl-4 = <0x1e>;
			rx_gpios = <0x09 0x10 0x00>;
			tx_gpios = <0x09 0x11 0x00>;
			status = "disable";
		};

		pwm@11006000 {
			compatible = "mediatek,mt8163-pwm";
			reg = <0x00 0x11006000 0x00 0x1000>;
			interrupts = <0x00 0x4d 0x08>;
			clocks = <0x05 0x0f 0x05 0x10 0x05 0x11 0x05 0x12>;
			clock-names = "PWM1-main\0PWM2-main\0PWM3-main\0PWM-main";
		};

		i2c@11007000 {
			compatible = "mediatek,mt8173-i2c";
			reg = <0x00 0x11007000 0x00 0x70 0x00 0x11000180 0x00 0x80>;
			interrupts = <0x00 0x54 0x08>;
			clock-div = <0x08>;
			clocks = <0x05 0x0b 0x05 0x29>;
			clock-names = "main\0dma";
			#address-cells = <0x01>;
			#size-cells = <0x00>;
			status = "okay";
			clock-frequency = <0x61a80>;
			pinctrl-names = "default";
			pinctrl-0 = <0x1f>;

			ft5x0x@38 {
				compatible = "mediatek,focaltp";
				reg = <0x38>;
				vdd_ana-supply = <0x20>;
				rst-gpio = <0x09 0x2e 0x00>;
				irq-gpio = <0x09 0x23 0x00>;
			};

			lp8557_led@2c {
				compatible = "ti,lp855x-led";
				reg = <0x2c>;
				epprom_data = <0x14c71301 0x1105122b 0x154216a0>;
			};

			kd_camera_hw1@3c {
				compatible = "mediatek,camera_main";
				reg = <0x3c>;
			};

			kd_camera_hw2@21 {
				compatible = "mediatek,camera_sub";
				reg = <0x21>;
			};

			goodix_ts@5d {
				compatible = "goodix,gt9xx";
				reg = <0x5d>;
				pinctrl-names = "irq_as_gpio\0irq_as_int";
				pinctrl-0 = <0x21>;
				pinctrl-1 = <0x22>;
				vdd_ana-supply = <0x20>;
				goodix,rst-gpio = <0x09 0x2e 0x00>;
				goodix,irq-gpio = <0x09 0x23 0x00>;
				goodix,cfg-group0 = [44 20 03 00 05 0a 35 00 01 08 1e 0f 50 32 01 05 00 00 00 00 13 13 00 18 1c 20 14 95 33 de 30 32 eb 17 00 00 00 bb 03 1c 00 00 00 00 00 00 00 00 00 00 00 23 37 81 e0 01 00 0a 00 04 92 24 00 8a 28 00 85 2b 00 7f 30 00 7d 34 00 7d 00 00 00 00 00 00 00 00 00 00 00 00 00 00 00 00 00 00 00 00 1e 00 00 00 00 00 00 00 00 00 00 00 00 00 00 00 18 17 14 13 10 0f 0c 0b 08 07 04 03 00 01 02 05 06 09 0a 0d 0e 11 12 15 16 19 1a ff ff ff 00 01 02 03 04 05 06 07 08 09 0a 0b 0c 0d 0e 0f 10 11 12 13 14 15 16 17 18 19 1b 1c 1d 1e 1f 20 21 22 23 25 24 26 28 27 ff ff d4 01];
				goodix,cfg-group1 = [44 20 03 00 05 0a 35 00 01 08 1e 0f 50 32 01 05 00 00 00 00 13 13 00 18 1c 20 14 95 33 de 30 32 eb 17 00 00 00 bb 03 1c 00 00 00 00 00 00 00 00 00 00 00 23 37 81 e0 01 00 0a 00 04 92 24 00 8a 28 00 85 2b 00 7f 30 00 7d 34 00 7d 00 00 00 00 00 00 00 00 00 00 00 00 00 00 00 00 00 00 00 00 1e 00 00 00 00 00 00 00 00 00 00 00 00 00 00 00 18 17 14 13 10 0f 0c 0b 08 07 04 03 00 01 02 05 06 09 0a 0d 0e 11 12 15 16 19 1a ff ff ff 00 01 02 03 04 05 06 07 08 09 0a 0b 0c 0d 0e 0f 10 11 12 13 14 15 16 17 18 19 1b 1c 1d 1e 1f 20 21 22 23 25 24 26 28 27 ff ff d4 01];
				goodix,cfg-group2 = [44 20 03 00 05 0a 35 00 01 08 1e 0f 50 32 01 05 00 00 00 00 13 13 00 18 1c 20 14 95 33 de 30 32 eb 17 00 00 00 bb 03 1c 00 00 00 00 00 00 00 00 00 00 00 23 37 81 e0 01 00 0a 00 04 92 24 00 8a 28 00 85 2b 00 7f 30 00 7d 34 00 7d 00 00 00 00 00 00 00 00 00 00 00 00 00 00 00 00 00 00 00 00 1e 00 00 00 00 00 00 00 00 00 00 00 00 00 00 00 18 17 14 13 10 0f 0c 0b 08 07 04 03 00 01 02 05 06 09 0a 0d 0e 11 12 15 16 19 1a ff ff ff 00 01 02 03 04 05 06 07 08 09 0a 0b 0c 0d 0e 0f 10 11 12 13 14 15 16 17 18 19 1b 1c 1d 1e 1f 20 21 22 23 25 24 26 28 27 ff ff d4 01];
				goodix,cfg-group3 = [44 20 03 00 05 0a 35 00 01 08 1e 0f 50 32 01 05 00 00 00 00 13 13 00 18 1c 20 14 95 33 de 30 32 eb 17 00 00 00 bb 03 1c 00 00 00 00 00 00 00 00 00 00 00 23 37 81 e0 01 00 0a 00 04 92 24 00 8a 28 00 85 2b 00 7f 30 00 7d 34 00 7d 00 00 00 00 00 00 00 00 00 00 00 00 00 00 00 00 00 00 00 00 1e 00 00 00 00 00 00 00 00 00 00 00 00 00 00 00 18 17 14 13 10 0f 0c 0b 08 07 04 03 00 01 02 05 06 09 0a 0d 0e 11 12 15 16 19 1a ff ff ff 00 01 02 03 04 05 06 07 08 09 0a 0b 0c 0d 0e 0f 10 11 12 13 14 15 16 17 18 19 1b 1c 1d 1e 1f 20 21 22 23 25 24 26 28 27 ff ff d4 01];
				goodix,cfg-group4 = [41 20 03 00 05 0a 35 00 01 08 20 08 5f 41 03 05 00 00 00 00 00 00 00 17 1a 1e 14 90 30 aa 28 2a eb 17 00 00 00 db 03 1c 00 00 00 00 00 00 00 00 00 00 00 0f 37 81 c0 02 00 0a 00 04 e3 11 00 bb 16 00 9d 1c 00 85 25 00 76 30 00 76 00 00 00 00 00 00 00 00 00 00 00 00 00 00 00 00 00 00 00 00 1e 00 00 00 00 00 00 00 00 00 00 00 00 00 00 00 00 01 02 03 04 05 06 07 08 09 0a 0b 0c 0d 0e 0f 10 11 12 13 ff ff ff ff ff ff ff ff ff ff 00 01 02 03 04 05 06 07 08 09 0a 0e 0f 10 11 12 15 16 17 18 19 1d 1e 1f 20 21 22 23 24 25 26 27 ff ff ff ff ff ff ff ff ff ff 51 01];
				goodix,cfg-group5 = [46 20 03 00 05 0a 35 00 01 08 1e 0f 50 32 01 05 00 00 00 00 13 14 00 17 1a 20 14 95 33 de 2a 2c 7f 1b 00 00 00 dc 03 1c 00 00 00 00 00 00 00 00 00 00 00 23 37 81 e0 01 00 0a 00 04 83 24 00 81 28 00 80 2b 00 80 30 00 80 34 00 80 00 00 00 00 00 00 00 00 00 00 00 00 00 00 00 00 00 00 00 00 1e 00 00 00 00 00 00 00 00 20 00 00 00 00 00 00 18 17 14 13 10 0f 0c 0b 08 07 04 03 00 01 02 05 06 09 0a 0d 0e 11 12 15 16 19 1a ff ff ff 00 01 02 03 04 05 06 07 08 09 0a 0b 0c 0d 0e 0f 10 11 12 13 14 15 16 17 18 19 1b 1c 1d 1e 1f 20 21 22 23 25 24 26 28 27 ff ff 1d 01];
			};
		};

		i2c@11008000 {
			compatible = "mediatek,mt8173-i2c";
			reg = <0x00 0x11008000 0x00 0x70 0x00 0x11000200 0x00 0x80>;
			interrupts = <0x00 0x55 0x08>;
			clock-div = <0x08>;
			clocks = <0x05 0x0c 0x05 0x29>;
			clock-names = "main\0dma";
			#address-cells = <0x01>;
			#size-cells = <0x00>;
			status = "okay";
			clock-frequency = <0x61a80>;
			pinctrl-names = "default";
			pinctrl-0 = <0x23>;

			sym827@60 {
				compatible = "silergy,sym827-regulator";
				reg = <0x60>;
				regulator-name = "vproc";
				regulator-min-microvolt = <0x927c0>;
				regulator-max-microvolt = <0x152bec>;
				regulator-enable-ramp-delay = <0x190>;
				regulator-ramp-delay = <0x208d>;
				regulator-always-on;
				vsel-gpio = <0x09 0x22 0x00>;
				linux,phandle = <0x70>;
				phandle = <0x70>;
			};
		};

		i2c@11009000 {
			compatible = "mediatek,mt8173-i2c";
			reg = <0x00 0x11009000 0x00 0x70 0x00 0x11000280 0x00 0x80>;
			interrupts = <0x00 0x56 0x08>;
			clock-div = <0x0a>;
			clocks = <0x05 0x0d 0x05 0x29>;
			clock-names = "main\0dma";
			#address-cells = <0x01>;
			#size-cells = <0x00>;
			status = "okay";
			clock-frequency = <0x61a80>;
			pinctrl-names = "default";
			pinctrl-0 = <0x24>;

			bq24296@6b {
				compatible = "ti,bq24297";
				reg = <0x6b>;
				interrupt-parent = <0x09>;
				interrupts = <0x01 0x02>;
				pinctrl-names = "bq24297_chg_en\0bq24297_interrupt_init";
				pinctrl-0 = <0x25>;
				pinctrl-1 = <0x26>;
			};

			alsps@44 {
				compatible = "mediatek,alsps";
				reg = <0x44>;
				status = "okay";
			};

			Douglas_gsensor@18 {
				compatible = "mediatek,bma_gsensor";
				reg = <0x18>;
				status = "okay";
			};

			tmp103-sensor@70 {
				compatible = "ti,tmp103_temp_sensor";
				reg = <0x70>;
				tmp103-sensor,offset = <0x8fc>;
				tmp103-sensor,alpha = <0x0a>;
				tmp103-sensor,weight = <0x00>;
			};

			tmp103-sensor@71 {
				compatible = "ti,tmp103_temp_sensor";
				reg = <0x71>;
				tmp103-sensor,offset = <0x2ee>;
				tmp103-sensor,alpha = <0x0a>;
				tmp103-sensor,weight = <0x00>;
			};

			tmp103-sensor@72 {
				compatible = "ti,tmp103_temp_sensor";
				reg = <0x72>;
				tmp103-sensor,offset = <0x2ee>;
				tmp103-sensor,alpha = <0x0a>;
				tmp103-sensor,weight = <0x00>;
			};

			g_sensor@6a {
				compatible = "mediatek,g_sensor";
				reg = <0x6a>;
			};

			gyro_sensor@6c {
				compatible = "mediatek,gyro_sensor";
				reg = <0x6c>;
			};
		};

		spi@1100a000 {
			compatible = "mediatek,mt8163-spi";
			#address-cells = <0x01>;
			#size-cells = <0x00>;
			reg = <0x00 0x1100a000 0x00 0x1000>;
			interrupts = <0x00 0x76 0x08>;
			clocks = <0x06 0x29 0x06 0x49 0x05 0x1b 0x05 0x41>;
			clock-names = "parent-clk\0sel-clk\0spi-clk\0dcm-sel-clk";
			pinctrl-names = "default";
			pinctrl-0 = <0x27>;
			status = "disabled";
		};

		thermal@1100b000 {
			compatible = "mediatek,mt8163-thermal";
			reg = <0x00 0x1100b000 0x00 0x1000>;
			interrupts = <0x00 0x4e 0x08>;
			clocks = <0x05 0x0a 0x05 0x21>;
			clock-names = "therm\0auxadc";
			apmixedsys = <0x28>;
		};

		ptp_od@1100b000 {
			compatible = "mediatek,mt8163-ptp_od";
			reg = <0x00 0x1100b000 0x00 0x1000>;
			interrupts = <0x00 0x7d 0x08>;
			clocks = <0x05 0x0a>;
			clock-names = "ptp_infra_therm";
		};

		btif@1100c000 {
			compatible = "mediatek,btif";
			reg = <0x00 0x1100c000 0x00 0x1000>;
			interrupts = <0x00 0x70 0x08>;
			clocks = <0x05 0x1a 0x05 0x29>;
			clock-names = "btifc\0apdmac";
		};

		usb@11200000 {
			compatible = "mediatek,mt8163-usb20";
			reg = <0x00 0x11200000 0x00 0x10000 0x00 0x11210000 0x00 0x10000>;
			interrupts = <0x00 0x48 0x08>;
			mode = <0x02>;
			multipoint = <0x01>;
			dyn_fifo = <0x01>;
			soft_con = <0x01>;
			dma = <0x01>;
			num_eps = <0x10>;
			dma_channels = <0x08>;
			clocks = <0x28 0x02 0x05 0x17 0x05 0x07 0x05 0x08>;
			clock-names = "usbpll\0usbmcu\0usb\0icusb";
			vusb-supply = <0x29>;
			pinctrl-names = "iddig_irq_init\0iddig_irq_low\0iddig_irq_high\0drvvbus_init\0drvvbus_low\0drvvbus_high\0otg5ven_init\0otg5ven_low\0otg5ven_high";
			pinctrl-0 = <0x2a>;
			pinctrl-1 = <0x2b>;
			pinctrl-2 = <0x2c>;
			pinctrl-3 = <0x2d>;
			pinctrl-4 = <0x2e>;
			pinctrl-5 = <0x2f>;
			pinctrl-6 = <0x30>;
			pinctrl-7 = <0x31>;
			pinctrl-8 = <0x32>;
			iddig_gpio = <0x09 0x26 0x00>;
			drvvbus_gpio = <0x09 0x1e 0x00>;
			otg5ven_gpio = <0x09 0x1d 0x00>;
			status = "okay";
		};

		usb@11270000 {
			compatible = "mediatek,mt8163-usb11";
			cell-index = <0x01>;
			reg = <0x00 0x11270000 0x00 0x10000 0x00 0x11210000 0x00 0x10000>;
			interrupts = <0x00 0x49 0x08>;
			mode = <0x02>;
			multipoint = <0x01>;
			dyn_fifo = <0x01>;
			soft_con = <0x01>;
			dma = <0x01>;
			num_eps = <0x08>;
			dma_channels = <0x04>;
			status = "disabled";
		};

		audiosys@11220000 {
			compatible = "mediatek,mt8163-audiosys\0syscon";
			reg = <0x00 0x11220000 0x00 0x1000>;
			#clock-cells = <0x01>;
			channel-type = <0x00>;
		};

		mt_soc_dl1_pcm@11220000 {
			compatible = "mediatek,mt8163-soc-pcm-dl1";
			reg = <0x00 0x11220000 0x00 0x1000 0x00 0x11221000 0x00 0x9000>;
			interrupts = <0x00 0x8e 0x08>;
			clocks = <0x05 0x30 0x06 0x4f 0x06 0x50 0x06 0x57 0x06 0x58 0x06 0x0a 0x06 0x0b 0x33>;
			clock-names = "aud_infra_clk\0top_mux_audio\0top_mux_audio_intbus\0aud_mux1_clk\0aud_mux2_clk\0apmixed_apll1_clk\0apmixed_apll2_clk\0top_clk26m_clk";
			audclk-gpio = <0x07 0x00>;
			audmiso-gpio = <0x08 0x00>;
			audmosi-gpio = <0x09 0x00>;
			extspkamp-gpio = <0x18 0x00>;
			i2s1clk-gpio = <0x30 0x00>;
			i2s1dat-gpio = <0x2e 0x00>;
			i2s1mclk-gpio = <0x0f 0x00>;
			i2s1ws-gpio = <0x2f 0x00>;
			power-domains = <0x34 0x05>;
			pinctrl-names = "default\0audpmicclk-mode0\0audpmicclk-mode1\0audi2s1-mode0\0audi2s1-mode1\0extamp-pullhigh\0extamp-pulllow\0hpamp-pullhigh\0hpamp-pulllow";
			pinctrl-0 = <0x35>;
			pinctrl-1 = <0x36>;
			pinctrl-2 = <0x37>;
			pinctrl-3 = <0x38>;
			pinctrl-4 = <0x39>;
			pinctrl-5 = <0x3a>;
			pinctrl-6 = <0x3b>;
			pinctrl-7 = <0x3c>;
			pinctrl-8 = <0x3d>;
			status = "okay";
		};

		mt_soc_ul1_pcm@11220000 {
			compatible = "mediatek,mt8163-soc-pcm-capture";
		};

		mt_soc_voice_md1@11220000 {
			compatible = "mediatek,mt8163-soc-pcm-voice-md1";
		};

		mt_soc_hdmi_pcm@11220000 {
			compatible = "mediatek,mt8163-soc-pcm-hdmi";
		};

		mt_soc_uldlloopback@11220000 {
			compatible = "mediatek,mt8163-soc-pcm-uldlloopback";
		};

		mt_soc_i2s0_pcm@11220000 {
			compatible = "mediatek,mt8163-soc-pcm-dl1-i2s0";
		};

		mt_soc_mrgrx_pcm@11220000 {
			compatible = "mediatek,mt8163-soc-pcm-mrgrx";
		};

		mt_soc_mrgrx_awb_pcm@11220000 {
			compatible = "mediatek,mt8163-soc-pcm-mrgrx-awb";
		};

		mt_soc_fm_i2s_pcm@11220000 {
			compatible = "mediatek,mt8163-soc-pcm-fm-i2s";
		};

		mt_soc_fm_i2s_awb_pcm@11220000 {
			compatible = "mediatek,mt8163-soc-pcm-fm-i2s-awb";
		};

		mt_soc_i2s0dl1_pcm@11220000 {
			compatible = "mediatek,mt8163-soc-pcm-dl1-i2s0Dl1";
		};

		mt_soc_dl1_awb_pcm@11220000 {
			compatible = "mediatek,mt8163-soc-pcm-dl1-awb";
		};

		mt_soc_voice_md1_bt@11220000 {
			compatible = "mediatek,mt8163-soc-pcm-voice-md1-bt";
		};

		mt_soc_voip_bt_out@11220000 {
			compatible = "mediatek,mt8163-soc-pcm-dl1-bt";
		};

		mt_soc_voip_bt_in@11220000 {
			compatible = "mediatek,mt8163-soc-pcm-bt-dai";
		};

		mt_soc_tdmrx_pcm@11220000 {
			compatible = "mediatek,mt8163-soc-tdm-capture";
		};

		mt_soc_fm_mrgtx_pcm@11220000 {
			compatible = "mediatek,mt8163-soc-pcm-fmtx";
		};

		mt_soc_ul2_pcm@11220000 {
			compatible = "mediatek,mt8163-soc-pcm-capture2";
		};

		mt_soc_i2s0_awb_pcm@11220000 {
			compatible = "mediatek,mt8163-soc-pcm-i2s0-awb";
		};

		mt_soc_voice_md2@11220000 {
			compatible = "mediatek,mt8163-soc-pcm-voice-md2";
		};

		mt_soc_routing_pcm@11220000 {
			compatible = "mediatek,mt8163-soc-pcm-routing";
		};

		mt_soc_voice_md2_bt@11220000 {
			compatible = "mediatek,mt8163-soc-pcm-voice-md2-bt";
		};

		mt_soc_hp_impedance@11220000 {
			compatible = "mediatek,mt8163-soc-pcm-hp-impedance";
		};

		mt_soc_codec_name@11220000 {
			compatible = "mediatek,mt8163-soc-codec-63xx";
		};

		mt_soc_dummy_pcm@11220000 {
			compatible = "mediatek,mt8163-soc-pcm-dummy";
		};

		mt_soc_codec_dummy_name@11220000 {
			compatible = "mediatek,mt8163-soc-codec-dummy";
		};

		mt_soc_routing_dai_name@11220000 {
			compatible = "mediatek,mt8163-soc-dai-routing";
		};

		mt_soc_dai_name@11220000 {
			compatible = "mediatek,mt8163-soc-dai-stub";
		};

		mfg@13000000 {
			compatible = "mediatek,mt8163-mfg\0mediatek,midgard-mfg";
			reg = <0x00 0x13000000 0x00 0x1000>;
			clocks = <0x06 0x46 0x06 0x18>;
			clock-names = "topck\0pll";
			power-domains = <0x34 0x00>;
		};

		gpu@13040000 {
			compatible = "arm,malit720\0arm,mali-t72x\0arm,malit7xx\0arm,mali-midgard";
			reg = <0x00 0x13040000 0x00 0x4000>;
			interrupts = <0x00 0xe3 0x08 0x00 0xe2 0x08 0x00 0xe1 0x08>;
			interrupt-names = "JOB\0MMU\0GPU";
			clock-frequency = <0x1efe9200>;
			power-domains = <0x34 0x07>;
		};

		mmc@11230000 {
			compatible = "mediatek,mt8163-mmc";
			reg = <0x00 0x11230000 0x00 0x1000>;
			interrupts = <0x00 0x4f 0x08>;
			infracfg = <0x05>;
			clocks = <0x05 0x1c 0x05 0x1f 0x3e>;
			clock-names = "extra\0source\0hclk";
			status = "okay";
			pinctrl-names = "default\0state_uhs";
			pinctrl-0 = <0x3f>;
			pinctrl-1 = <0x40>;
			bus-width = <0x08>;
			latch-ck = <0x01>;
			max-frequency = <0xbebc200>;
			cap-mmc-highspeed;
			mmc-hs200-1_8v;
			cap-mmc-hw-reset;
			vmmc-supply = <0x41>;
			vqmmc-supply = <0x42>;
			non-removable;
		};

		mmc@11240000 {
			compatible = "mediatek,mt8163-mmc";
			reg = <0x00 0x11240000 0x00 0x1000>;
			interrupts = <0x00 0x50 0x08>;
			clocks = <0x05 0x1d 0x06 0x4b 0x3e>;
			clock-names = "sd_extra\0source\0hclk";
			status = "okay";
			pinctrl-names = "default\0state_uhs";
			pinctrl-0 = <0x43>;
			pinctrl-1 = <0x44>;
			bus-width = <0x04>;
			latch-ck = <0x01>;
			max-frequency = <0xbebc200>;
			cap-sd-highspeed;
			sd-uhs-sdr50;
			sd-uhs-sdr104;
			cd-gpios = <0x09 0x31 0x00>;
			cd-inverted;
			vmmc-supply = <0x45>;
			vqmmc-supply = <0x46>;
		};

		mmsys@14000000 {
			compatible = "mediatek,mt8163-mmsys\0syscon";
			reg = <0x00 0x14000000 0x00 0x1000>;
			#clock-cells = <0x01>;
			linux,phandle = <0x0a>;
			phandle = <0x0a>;
		};

		mdp_rdma@14001000 {
			compatible = "mediatek,mt8163-mdp_rdma";
			reg = <0x00 0x14001000 0x00 0x1000>;
			interrupts = <0x00 0xb2 0x08>;
		};

		mdp_rsz0@14002000 {
			compatible = "mediatek,mt8163-mdp_rsz0";
			reg = <0x00 0x14002000 0x00 0x1000>;
			interrupts = <0x00 0xb3 0x08>;
		};

		mdp_rsz1@14003000 {
			compatible = "mediatek,mt8163-mdp_rsz1";
			reg = <0x00 0x14003000 0x00 0x1000>;
			interrupts = <0x00 0xb4 0x08>;
		};

		mdp_wdma@14004000 {
			compatible = "mediatek,mt8163-mdp_wdma";
			reg = <0x00 0x14004000 0x00 0x1000>;
			interrupts = <0x00 0xb6 0x08>;
		};

		mdp_wrot@14005000 {
			compatible = "mediatek,mt8163-mdp_wrot";
			reg = <0x00 0x14005000 0x00 0x1000>;
			interrupts = <0x00 0xb7 0x08>;
		};

		mdp_tdshp@14006000 {
			compatible = "mediatek,mt8163-mdp_tdshp0";
			reg = <0x00 0x14006000 0x00 0x1000>;
			interrupts = <0x00 0xb5 0x08>;
		};

		mt8163-dispsys {
			compatible = "mediatek,mt8163-dispsys";
		};

		disp_ovl0@14007000 {
			compatible = "mediatek,mt8163-disp_ovl0";
			reg = <0x00 0x14007000 0x00 0x1000>;
			interrupts = <0x00 0xb8 0x08>;
		};

		disp_ovl1@14008000 {
			compatible = "mediatek,mt8163-disp_ovl1";
			reg = <0x00 0x14008000 0x00 0x1000>;
			interrupts = <0x00 0xb9 0x08>;
		};

		disp_rdma0@14009000 {
			compatible = "mediatek,mt8163-disp_rdma0";
			reg = <0x00 0x14009000 0x00 0x1000>;
			interrupts = <0x00 0xba 0x08>;
		};

		disp_rdma1@1400a000 {
			compatible = "mediatek,mt8163-disp_rdma1";
			reg = <0x00 0x1400a000 0x00 0x1000>;
			interrupts = <0x00 0xbb 0x08>;
		};

		disp_wdma0@1400b000 {
			compatible = "mediatek,mt8163-disp_wdma0";
			reg = <0x00 0x1400b000 0x00 0x1000>;
			interrupts = <0x00 0xbc 0x08>;
		};

		disp_color@1400c000 {
			compatible = "mediatek,mt8163-disp_color";
			reg = <0x00 0x1400c000 0x00 0x1000>;
			interrupts = <0x00 0xbd 0x08>;
		};

		disp_ccorr@1400d000 {
			compatible = "mediatek,mt8163-disp_ccorr";
			reg = <0x00 0x1400d000 0x00 0x1000>;
			interrupts = <0x00 0xbe 0x08>;
		};

		disp_aal@1400e000 {
			compatible = "mediatek,mt8163-disp_aal";
			reg = <0x00 0x1400e000 0x00 0x1000>;
			interrupts = <0x00 0xbf 0x08>;
		};

		disp_gamma@1400f000 {
			compatible = "mediatek,mt8163-disp_gamma";
			reg = <0x00 0x1400f000 0x00 0x1000>;
			interrupts = <0x00 0xc0 0x08>;
		};

		disp_dither@14010000 {
			compatible = "mediatek,mt8163-disp_dither";
			reg = <0x00 0x14010000 0x00 0x1000>;
			interrupts = <0x00 0xc1 0x08>;
		};

		disp_ufoe@14011000 {
			compatible = "mediatek,mt8163-disp_ufoe";
			reg = <0x00 0x14011000 0x00 0x1000>;
		};

		disp_dsi0@14012000 {
			compatible = "mediatek,mt8163-disp_dsi0";
			reg = <0x00 0x14012000 0x00 0x1000>;
			interrupts = <0x00 0xc3 0x08>;
		};

		disp_dpi0@14013000 {
			compatible = "mediatek,mt8163-disp_dpi0";
			reg = <0x00 0x14013000 0x00 0x1000>;
			interrupts = <0x00 0xc4 0x08>;
		};

		disp_dpi1@1401c000 {
			compatible = "mediatek,mt8163-disp_dpi1";
			reg = <0x00 0x1401c000 0x00 0x1000>;
			interrupts = <0x00 0xc9 0x08>;
		};

		disp_pwm0@14014000 {
			compatible = "mediatek,mt8163-disp_pwm";
			reg = <0x00 0x14014000 0x00 0x1000>;
		};

		mm_mutex@14015000 {
			compatible = "mediatek,mt8163-disp_mutex";
			reg = <0x00 0x14015000 0x00 0x1000>;
			interrupts = <0x00 0xb1 0x08>;
		};

		disp_wdma1@14018000 {
			compatible = "mediatek,mt8163-disp_wdma1";
			reg = <0x00 0x14018000 0x00 0x1000>;
			interrupts = <0x00 0xc6 0x08>;
		};

		disp_config2@10206000 {
			compatible = "mediatek,mt8163-disp_config2";
			reg = <0x00 0x10206000 0x00 0x1000>;
		};

		disp_config3@10000000 {
			compatible = "mediatek,mt8163-disp_config3";
			reg = <0x00 0x10000000 0x00 0x1000>;
		};

		disp_mipi@10215000 {
			compatible = "mediatek,mt8163-disp_mipi";
			reg = <0x00 0x10215000 0x00 0x1000>;
		};

		disp_io_driving@10005000 {
			compatible = "mediatek,mt8163-disp_io_driving";
			reg = <0x00 0x10005000 0x00 0x1000>;
		};

		disp_tvdpll_cfg6@100000a0 {
			compatible = "mediatek,mt8163-disp_tvdpll_cfg6";
			reg = <0x00 0x100000a0 0x00 0x1000>;
		};

		disp_tvdpll_con0@1000c270 {
			compatible = "mediatek,mt8163-disp_tvdpll_con0";
			reg = <0x00 0x1000c270 0x00 0x1000>;
		};

		disp_tvdpll_con1@1000c274 {
			compatible = "mediatek,mt8163-disp_tvdpll_con1";
			reg = <0x00 0x1000c274 0x00 0x1000>;
		};

		disp_lvds_ana@10215800 {
			compatible = "mediatek,mt8163-disp_lvds_ana";
			reg = <0x00 0x10215800 0x00 0x1000>;
		};

		g3d_iommu@13005000 {
			cell-index = <0x02>;
			compatible = "mediatek,mt8163-g3d_iommu";
			reg = <0x00 0x13005000 0x00 0x1000>;
			interrupts = <0x00 0xe2 0x08>;
		};

		larb@14016000 {
			compatible = "mediatek,mt8163-smi-larb";
			reg = <0x00 0x14016000 0x00 0x1000>;
			interrupts = <0x00 0xcd 0x08>;
			mediatek,smi = <0x47>;
			mediatek,larbid = <0x00>;
			clocks = <0x0a 0x01 0x0a 0x01>;
			clock-names = "apb\0smi";
			power-domains = <0x34 0x00>;
		};

		smi@14017000 {
			compatible = "mediatek,mt8163-smi";
			reg = <0x00 0x14017000 0x00 0x1000>;
			clocks = <0x0a 0x00 0x0a 0x00>;
			clock-names = "apb\0smi";
			power-domains = <0x34 0x00>;
			linux,phandle = <0x47>;
			phandle = <0x47>;
		};

		disp_lvds_tx@1401b200 {
			compatible = "mediatek,mt8163-disp_lvds_tx";
			reg = <0x00 0x1401b200 0x00 0x1000>;
		};

		hdmi@1401d000 {
			compatible = "mediatek,mt8163-hdmitx";
			power-domains = <0x34 0x00>;
			reg = <0x00 0x1401d000 0x00 0x390 0x00 0x1100f000 0x00 0x10 0x00 0x10013000 0x00 0xbc>;
			interrupts = <0x00 0xca 0x08>;
			clocks = <0x05 0x25 0x05 0x26 0x0a 0x2a 0x0a 0x2d 0x0a 0x2c 0x0a 0x2b>;
			clock-names = "cec_pdn\0clk_cec_26m\0mmsys_hdmi_pll\0mmsys_hdmi_pixel\0mmsys_hdmi_audio\0mmsys_hdmi_spidif";
		};

		imgsys@15000000 {
			compatible = "mediatek,mt8163-imgsys\0syscon";
			reg = <0x00 0x15000000 0x00 0x1000>;
			#clock-cells = <0x01>;
			linux,phandle = <0x48>;
			phandle = <0x48>;
		};

		isp_display {
			compatible = "mediatek,mt8163-isp_display";
		};

		ispsys@15000000 {
			compatible = "mediatek,mt8163-ispsys";
			reg = <0x00 0x15004000 0x00 0x9000 0x00 0x15000000 0x00 0x10000 0x00 0x10217000 0x00 0x3000>;
			interrupts = <0x00 0xda 0x08 0x00 0xdb 0x08>;
			clocks = <0x48 0x00 0x48 0x02 0x48 0x03 0x48 0x04 0x48 0x05 0x48 0x06 0x0a 0x00>;
			clock-names = "IMG_LARB2_SMI\0IMG_CAM_SMI\0IMG_CAM_CAM\0IMG_SEN_TG\0IMG_SEN_CAM\0IMG_CAM_SV\0MM_SMI_COMMON";
		};

		larb@15001000 {
			compatible = "mediatek,mt8163-smi-larb";
			reg = <0x00 0x15001000 0x00 0x1000>;
			interrupts = <0x00 0xd9 0x08>;
			mediatek,smi = <0x47>;
			mediatek,larbid = <0x02>;
			clocks = <0x48 0x00 0x48 0x00>;
			clock-names = "apb\0smi";
			power-domains = <0x34 0x03>;
		};

		camera1@15008000 {
			compatible = "mediatek,mt8163-camera_hw";
			reg = <0x00 0x15008000 0x00 0x1000>;
			clocks = <0x06 0x47 0x06 0x36 0x06 0x39>;
			clock-names = "TOP_CAMTG_SEL\0TOP_UNIVPLL_D26\0TOP_UNIVPLL2_D2";
			reg-vcama-supply = <0x49>;
			reg-vcamd-supply = <0x4a>;
			reg-vcamio-supply = <0x4b>;
			reg-vcami2c-supply = <0x42>;
			pinctrl-names = "default\0cam0_rst0\0cam0_rst1\0cam0_pnd0\0cam0_pnd1\0cam1_rst0\0cam1_rst1\0cam1_pnd0\0cam1_pnd1\0cam_ldo0_0\0cam_ldo0_1";
			pinctrl-0 = <0x4c>;
			pinctrl-1 = <0x4d>;
			pinctrl-2 = <0x4e>;
			pinctrl-3 = <0x4f>;
			pinctrl-4 = <0x50>;
			pinctrl-5 = <0x51>;
			pinctrl-6 = <0x52>;
			pinctrl-7 = <0x53>;
			pinctrl-8 = <0x54>;
			status = "okay";
		};

		camera2@15008000 {
			compatible = "mediatek,mt8163-camera_hw2";
			reg = <0x00 0x15008000 0x00 0x1000>;
			reg-vcama-supply = <0x49>;
			reg-vcamd-supply = <0x4a>;
			reg-vcamio-supply = <0x4b>;
			reg-vcami2c-supply = <0x42>;
		};

		vdecsys@16000000 {
			compatible = "mediatek,mt8163-vdecsys\0syscon";
			reg = <0x00 0x16000000 0x00 0x1000>;
			#clock-cells = <0x01>;
			linux,phandle = <0x55>;
			phandle = <0x55>;
		};

		vdec_gcon@16000000 {
			compatible = "mediatek,mt8163-vdec_gcon";
			reg = <0x00 0x16000000 0x00 0x10000>;
		};

		larb@16010000 {
			compatible = "mediatek,mt8163-smi-larb";
			reg = <0x00 0x16010000 0x00 0x10000>;
			interrupts = <0x00 0xd5 0x08>;
			mediatek,smi = <0x47>;
			mediatek,larbid = <0x01>;
			clocks = <0x55 0x00 0x55 0x01>;
			clock-names = "apb\0smi";
			power-domains = <0x34 0x01>;
		};

		vdec@16020000 {
			compatible = "mediatek,mt8163-vdec";
			reg = <0x00 0x16020000 0x00 0x10000>;
			interrupts = <0x00 0xd4 0x08>;
		};

		vencsys@17000000 {
			compatible = "mediatek,mt8163-vencsys\0syscon";
			reg = <0x00 0x17000000 0x00 0x1000>;
			#clock-cells = <0x01>;
			linux,phandle = <0x56>;
			phandle = <0x56>;
		};

		larb@17001000 {
			compatible = "mediatek,mt8163-smi-larb";
			reg = <0x00 0x17001000 0x00 0x1000>;
			interrupts = <0x00 0xcf 0x08>;
			mediatek,smi = <0x47>;
			mediatek,larbid = <0x03>;
			clocks = <0x56 0x01 0x56 0x00>;
			clock-names = "apb\0smi";
			power-domains = <0x34 0x02>;
		};

		venc@17002000 {
			compatible = "mediatek,mt8163-venc";
			reg = <0x00 0x17002000 0x00 0x1000>;
			interrupts = <0x00 0xce 0x08>;
		};

		jpgenc@17003000 {
			compatible = "mediatek,mt8163-jpgenc\0mediatek,jpgenc";
			reg = <0x00 0x17003000 0x00 0x1000>;
			interrupts = <0x00 0xd0 0x08>;
			clocks = <0x56 0x02>;
			clock-names = "venc-jpgenc";
		};

		btcvsd@18000000 {
			compatible = "mediatek,mt8163-audio_bt_cvsd\0mediatek,audio_bt_cvsd";
			offset = <0xf00 0x800 0xfd0 0xfd4 0xfd8>;
			reg = <0x00 0x10001000 0x00 0x1000 0x00 0x18000000 0x00 0x10000 0x00 0x18080000 0x00 0x8000>;
			interrupts = <0x00 0xec 0x08>;
		};

		consys@18070000 {
			compatible = "mediatek,mt8163-consys";
			reg = <0x00 0x18070000 0x00 0x200 0x00 0x10007000 0x00 0x100 0x00 0x10001000 0x00 0x1000>;
			power-domains = <0x34 0x04>;
			interrupts = <0x00 0xed 0x08 0x00 0xec 0x08>;
			pinctrl-names = "default\0gps_lna_state_init\0gps_lna_state_oh\0gps_lna_state_ol\0wifi_reset_init";
			pinctrl-0 = <0x57>;
			pinctrl-1 = <0x58>;
			pinctrl-2 = <0x59>;
			pinctrl-3 = <0x5a>;
			pinctrl-4 = <0x5b>;
			vcn18-supply = <0x5c>;
			vcn28-supply = <0x5d>;
			vcn33_bt-supply = <0x5e>;
			vcn33_wifi-supply = <0x5f>;
			status = "okay";
		};

		wifi@180f0000 {
			compatible = "mediatek,wifi";
			reg = <0x00 0x180f0000 0x00 0x5c>;
			interrupts = <0x00 0xee 0x08>;
			clocks = <0x05 0x29>;
			clock-names = "wifi-dma";
		};

		accdet@ {
			compatible = "mediatek,mt8163-accdet";
			interrupt-parent = <0x09>;
			interrupts = <0x04 0x04>;
			eint-debounce = <0x3e800>;
			accdet-gpio = <0x09 0x1a 0x00>;
			accdet-mic-vol = <0x07>;
			headset-mode-setting = <0x500 0x200 0x01 0x1f0 0x800 0x800 0x4000>;
			accdet-plugout-debounce = <0x3e8>;
			accdet-mic-mode = <0x01>;
			headset-three-key-threshold = <0x00 0x50 0xdc 0x1f4>;
			headset-four-key-threshold = <0x00 0x3a 0x79 0xc0 0x1c2>;
			pinctrl-names = "default\0state_eint_as_int\0typeswitchIC-off\0typeswitchIC-on";
			pinctrl-0 = <0x60>;
			pinctrl-1 = <0x61>;
			pinctrl-2 = <0x62>;
			pinctrl-3 = <0x63>;
			accdet-vcamaf-supply = <0x64>;
			status = "okay";
		};

		touch@ {
			compatible = "mediatek,mt8163-touch";
			vtouch-supply = <0x20>;
			tpd-resolution = <0x2d0 0x500>;
			use-tpd-button = <0x00>;
			tpd-key-num = <0x04>;
			tpd-key-local = <0x8b 0xac 0x9e 0x00>;
			tpd-key-dim-local = <0x3c 0x352 0x32 0x1e 0xb4 0x352 0x32 0x1e 0x12c 0x352 0x32 0x1e 0x1a4 0x352 0x32 0x1e>;
			tpd-max-touch-num = <0x05>;
			tpd-filter-enable = <0x01>;
			tpd-filter-pixel-density = <0x7c>;
			tpd-filter-custom-prameters = <0x00 0x00 0x00 0x00 0x00 0x00 0x00 0x00 0x00 0x00 0x00 0x00>;
			tpd-filter-custom-speed = <0x00 0x00 0x00>;
			pinctrl-names = "default\0state_eint_as_int\0state_eint_output0\0state_eint_output1\0state_rst_output0\0state_rst_output1";
			pinctrl-0 = <0x65>;
			pinctrl-1 = <0x22>;
			pinctrl-2 = <0x21>;
			pinctrl-3 = <0x66>;
			pinctrl-4 = <0x67>;
			pinctrl-5 = <0x68>;
			status = "okay";
		};

		hwmsensor@0 {
			compatible = "mediatek,hwmsensor";
		};

		gsensor@0 {
			compatible = "mediatek,gsensor";
		};

		als_ps@0 {
			compatible = "mediatek,als_ps";
			pinctrl-names = "pin_default\0pin_cfg";
			pinctrl-0 = <0x69>;
			pinctrl-1 = <0x6a>;
			status = "okay";
		};

		batchsensor@0 {
			compatible = "mediatek,batchsensor";
		};

		gyroscope@0 {
			compatible = "mediatek,gyroscope";
		};

		barometer@0 {
			compatible = "mediatek,barometer";
		};

		msensor@0 {
			compatible = "mediatek,msensor";
		};

		orientation@0 {
			compatible = "mediatek,orientation";
		};

		led@0 {
			compatible = "mediatek,red";
			led_mode = <0x00>;
			data;
			pwm_config = <0x00 0x00 0x00 0x00 0x00>;
		};

		led@1 {
			compatible = "mediatek,green";
			led_mode = <0x00>;
			data;
			pwm_config = <0x00 0x00 0x00 0x00 0x00>;
		};

		led@2 {
			compatible = "mediatek,blue";
			led_mode = <0x00>;
			data;
			pwm_config = <0x00 0x00 0x00 0x00 0x00>;
		};

		led@3 {
			compatible = "mediatek,jogball-backlight";
			led_mode = <0x00>;
			data;
			pwm_config = <0x00 0x00 0x00 0x00 0x00>;
		};

		led@4 {
			compatible = "mediatek,keyboard-backlight";
			led_mode = <0x00>;
			data;
			pwm_config = <0x00 0x00 0x00 0x00 0x00>;
		};

		led@5 {
			compatible = "mediatek,button-backlight";
			led_mode = <0x00>;
			data;
			pwm_config = <0x00 0x00 0x00 0x00 0x00>;
		};

		led@6 {
			compatible = "mediatek,lcd-backlight";
			led_mode = <0x05>;
			data;
			pwm_config = <0x00 0x00 0x00 0x00 0x00>;
			gpios = <0x09 0x2b 0x00>;
		};

		mtkfb@0 {
			compatible = "mediatek,MTKFB";
			clocks = <0x0a 0x09 0x0a 0x0a 0x0a 0x0b 0x0a 0x0c 0x0a 0x0d 0x0a 0x0e 0x0a 0x17 0x0a 0x0f 0x0a 0x10 0x0a 0x11 0x0a 0x12 0x0a 0x13 0x0a 0x14 0x0a 0x20 0x0a 0x21 0x0a 0x22 0x0a 0x23 0x0a 0x24 0x0a 0x25 0x0a 0x26 0x0a 0x27 0x0a 0x28 0x0a 0x29 0x0a 0x2e 0x0a 0x2f 0x06 0x55 0x28 0x0a 0x06 0x14 0x06 0x15 0x06 0x16 0x06 0x59 0x28 0x06 0x06 0x2d 0x06 0x2e 0x06 0x2f 0x06 0x30 0x06 0x44>;
			clock-names = "MMSYS_CLK_FAKE_ENG\0MMSYS_CLK_DISP_OVL0\0MMSYS_CLK_DISP_OVL1\0MMSYS_CLK_DISP_RDMA0\0MMSYS_CLK_DISP_RDMA1\0MMSYS_CLK_DISP_WDMA0\0MMSYS_CLK_DISP_WDMA1\0MMSYS_CLK_DISP_COLOR\0MMSYS_CLK_DISP_CCORR\0MMSYS_CLK_DISP_AAL\0MMSYS_CLK_DISP_GAMMA\0MMSYS_CLK_DISP_DITHER\0MMSYS_CLK_DISP_UFOE\0MMSYS_CLK_DISP_PWM\0MMSYS_CLK_DISP_PWM26M\0MMSYS_CLK_DSI_ENGINE\0MMSYS_CLK_DSI_DIGITAL\0MMSYS_CLK_DPI0_PIXEL\0MMSYS_CLK_DPI0_ENGINE\0MMSYS_CLK_LVDS_PIXEL\0MMSYS_CLK_LVDS_CTS\0MMSYS_CLK_DPI1_PIXEL\0MMSYS_CLK_DPI1_ENGINE\0MMSYS_CLK_DISP_DSC_ENGINE\0MMSYS_CLK_DISP_DSC_MEM\0MMSYS_CLK_MUX_DPI0_SEL\0MMSYS_APMIXED_LVDSPLL\0MMSYS_CLK_MUX_LVDSPLL_D2\0MMSYS_CLK_MUX_LVDSPLL_D4\0MMSYS_CLK_MUX_LVDSPLL_D8\0MMSYS_CLK_MUX_DPI1_SEL\0MMSYS_APMIXED_TVDPLL\0MMSYS_CLK_MUX_TVDPLL_D2\0MMSYS_CLK_MUX_TVDPLL_D4\0MMSYS_CLK_MUX_TVDPLL_D8\0MMSYS_CLK_MUX_TVDPLL_D16\0MMSYS_CLK_PWM_SEL";
		};

		ice_debug {
			compatible = "mediatek,mt8163-ice_debug\0mediatek,mt8173-ice_debug";
			clocks = <0x05 0x2f>;
			clock-names = "ice_dbg";
		};

		bat_meter {
			compatible = "mediatek,bat_meter";
			vbat_channel_number = <0x06>;
			isense_channel_number = <0x07>;
			vbattemp_channel_number = <0x05>;
			vcharger_channel_number = <0x04>;
			swchr_power_path = <0x01>;
			external_swchr_support = <0x01>;
			r_bat_sense = <0x04>;
			r_i_sense = <0x04>;
			r_charger_1 = <0x14a>;
			r_charger_2 = <0x27>;
			temperature_t0 = <0x6e>;
			temperature_t1 = <0x00>;
			temperature_t1_5 = <0x0a>;
			temperature_t2 = <0x19>;
			temperature_t3 = <0x32>;
			temperature_t = <0xff>;
			fg_meter_resistance = <0x00>;
			q_max_pos_50 = <0x1251>;
			q_max_pos_25 = <0x133b>;
			q_max_pos_10 = <0x121b>;
			q_max_pos_0 = <0x10e0>;
			q_max_neg_10 = <0xfd2>;
			q_max_pos_50_h_current = <0x11dd>;
			q_max_pos_25_h_current = <0x12dd>;
			q_max_pos_10_h_current = <0x11dc>;
			q_max_pos_0_h_current = <0xec1>;
			q_max_neg_10_h_current = <0xa49>;
			oam_d5 = <0x00>;
			change_tracking_point = <0x01>;
			cust_tracking_point = <0x0e>;
			cust_r_sense = <0xc8>;
			cust_hw_cc = <0x00>;
			aging_tuning_value = <0x64>;
			cust_r_fg_offset = <0x00>;
			ocv_board_compesate = <0x00>;
			r_fg_board_base = <0x3e8>;
			r_fg_board_slope = <0x3e8>;
			car_tune_value = <0x64>;
			current_detect_r_fg = <0x0a>;
			minerroroffset = <0x3e8>;
			fg_vbat_average_size = <0x12>;
			r_fg_value = <0x0a>;
			cust_poweron_delta_capacity_tolrance = <0x50>;
			cust_poweron_low_capacity_tolrance = <0x05>;
			cust_poweron_max_vbat_tolrance = <0x46>;
			cust_poweron_delta_vbat_tolrance = <0x3c>;
			cust_poweron_delta_hw_sw_ocv_capacity_tolrance = <0x0a>;
			fixed_tbat_25 = <0x00>;
			vbat_normal_wakeup = <0xe10>;
			vbat_low_power_wakeup = <0xdac>;
			normal_wakeup_period = <0x1518>;
			low_power_wakeup_period = <0x12c>;
			close_poweroff_wakeup_period = <0x1e>;
			rbat_pull_up_r = <0xf1cc>;
			rbat_pull_down_r = <0x1a1f8>;
			rbat_pull_up_volt = <0x708>;
			step_of_qmax = <0x3c>;
			std_loading_current = <0x1770>;
			vbat_internal_charging = <0x07>;
			isense_internal_charging = <0x06>;
			q_max_pos_50_1 = <0x1224>;
			q_max_pos_25_1 = <0x12c1>;
			q_max_pos_10_1 = <0x11b8>;
			q_max_pos_0_1 = <0x11b8>;
			q_max_neg_10_1 = <0x1116>;
			q_max_pos_50_h_current_1 = <0x119b>;
			q_max_pos_25_h_current_1 = <0x1262>;
			q_max_pos_10_h_current_1 = <0x1165>;
			q_max_pos_0_h_current_1 = <0x1134>;
			q_max_neg_10_h_current_1 = <0x1046>;
			q_max_pos_50_500cycle = <0x11bf>;
			q_max_pos_25_500cycle = <0x11b8>;
			q_max_pos_10_500cycle = <0x11ff>;
			q_max_pos_0_500cycle = <0x11de>;
			q_max_neg_10_500cycle = <0x106c>;
			q_max_pos_50_h_current_500cycle = <0x119e>;
			q_max_pos_25_h_current_500cycle = <0x118f>;
			q_max_pos_10_h_current_500cycle = <0x1172>;
			q_max_pos_0_h_current_500cycle = <0x1072>;
			q_max_neg_10_h_current_500cycle = <0x592>;
			q_max_pos_50_500cycle_1 = <0x1180>;
			q_max_pos_25_500cycle_1 = <0x119e>;
			q_max_pos_10_500cycle_1 = <0x1191>;
			q_max_pos_0_500cycle_1 = <0x11c6>;
			q_max_neg_10_500cycle_1 = <0x1185>;
			q_max_pos_50_h_current_500cycle_1 = <0x1158>;
			q_max_pos_25_h_current_500cycle_1 = <0x1176>;
			q_max_pos_10_h_current_500cycle_1 = <0x115f>;
			q_max_pos_0_h_current_500cycle_1 = <0x117c>;
			q_max_neg_10_h_current_500cycle_1 = <0x10e4>;
			batt_temperature_table_num = <0x11>;
			batt_temperature_table = <0xffffffec 0x7a0bc 0xfffffff1 0x5ab90 0xfffffff6 0x440ac 0xfffffffb 0x33770 0x00 0x27420 0x05 0x1e398 0x0a 0x1771e 0x0f 0x1255c 0x14 0xe736 0x19 0xb798 0x1e 0x92d6 0x23 0x763e 0x28 0x5fdc 0x2d 0x4e34 0x32 0x402e 0x37 0x3502 0x3c 0x2c06>;
			battery_profile_t0_num = <0x50>;
			battery_profile_t0 = <0x00 0x1047 0x01 0x1012 0x03 0xfef 0x04 0xfd5 0x05 0xfba 0x07 0xf9d 0x08 0xf87 0x09 0xf7c 0x0b 0xf76 0x0c 0xf70 0x0d 0xf6c 0x0f 0xf67 0x10 0xf62 0x11 0xf5e 0x13 0xf58 0x14 0xf53 0x15 0xf4d 0x17 0xf46 0x18 0xf40 0x19 0xf39 0x1b 0xf31 0x1c 0xf29 0x1d 0xf20 0x1f 0xf18 0x20 0xf0f 0x21 0xf08 0x23 0xf01 0x24 0xefa 0x25 0xef4 0x27 0xeef 0x28 0xeeb 0x29 0xee7 0x2b 0xee3 0x2c 0xedf 0x2d 0xedc 0x2f 0xed9 0x30 0xed6 0x31 0xed4 0x33 0xed2 0x34 0xed0 0x35 0xecf 0x37 0xece 0x38 0xecc 0x39 0xecb 0x3b 0xeca 0x3c 0xec9 0x3d 0xec7 0x3f 0xec6 0x40 0xec4 0x41 0xec2 0x43 0xec0 0x44 0xebf 0x45 0xebc 0x47 0xeba 0x48 0xeb8 0x49 0xeb5 0x4b 0xeb2 0x4c 0xeaf 0x4d 0xeab 0x4f 0xea8 0x50 0xea4 0x51 0xe9f 0x53 0xe9b 0x54 0xe94 0x55 0xe90 0x57 0xe8a 0x58 0xe84 0x59 0xe7f 0x5b 0xe7a 0x5c 0xe76 0x5d 0xe73 0x5f 0xe6e 0x60 0xe68 0x61 0xe5d 0x63 0xe45 0x64 0xe19 0x64 0xe19 0x64 0xe19 0x64 0xe19 0x64 0xe19>;
			battery_profile_t0_num_1 = <0x50>;
			battery_profile_t0_1 = <0x00 0x1043 0x01 0x1043 0x02 0x102f 0x04 0x1018 0x05 0xff8 0x06 0xfe2 0x07 0xfd4 0x09 0xfc9 0x0a 0xfbe 0x0b 0xfb5 0x0c 0xfac 0x0e 0xfa4 0x0f 0xf9c 0x10 0xf94 0x11 0xf8c 0x13 0xf85 0x14 0xf7d 0x15 0xf76 0x16 0xf6f 0x17 0xf68 0x19 0xf61 0x1a 0xf5a 0x1b 0xf54 0x1c 0xf4d 0x1e 0xf46 0x1f 0xf40 0x20 0xf39 0x21 0xf32 0x23 0xf2b 0x24 0xf24 0x25 0xf1d 0x26 0xf16 0x28 0xf0f 0x29 0xf09 0x2a 0xf03 0x2b 0xefd 0x2c 0xef8 0x2e 0xef3 0x2f 0xeee 0x30 0xeea 0x31 0xee6 0x33 0xee3 0x34 0xedf 0x35 0xedc 0x36 0xed9 0x38 0xed6 0x39 0xed4 0x3a 0xed2 0x3b 0xecf 0x3c 0xecd 0x3e 0xecc 0x3f 0xeca 0x41 0xec6 0x43 0xec5 0x45 0xec1 0x46 0xec0 0x48 0xebe 0x49 0xebb 0x4a 0xeb9 0x4b 0xeb6 0x4d 0xeb3 0x4e 0xeaf 0x4f 0xeab 0x50 0xea6 0x51 0xea0 0x53 0xe9a 0x54 0xe93 0x55 0xe8c 0x56 0xe83 0x58 0xe7a 0x59 0xe70 0x5a 0xe66 0x5b 0xe5e 0x5d 0xe57 0x5e 0xe4e 0x5f 0xe43 0x60 0xe30 0x62 0xe0a 0x63 0xdca 0x64 0xd6d>;
			battery_profile_t1_num = <0x50>;
			battery_profile_t1 = <0x00 0x1044 0x01 0x100f 0x03 0xfed 0x04 0xfd1 0x05 0xfb5 0x06 0xfa3 0x08 0xf96 0x09 0xf8c 0x0a 0xf84 0x0b 0xf7e 0x0d 0xf79 0x0e 0xf75 0x0f 0xf72 0x10 0xf6f 0x12 0xf6b 0x13 0xf67 0x14 0xf62 0x15 0xf5c 0x17 0xf56 0x18 0xf50 0x19 0xf4a 0x1a 0xf44 0x1c 0xf3e 0x1d 0xf37 0x1e 0xf31 0x1f 0xf2a 0x21 0xf22 0x22 0xf19 0x23 0xf10 0x24 0xf08 0x26 0xf00 0x27 0xef9 0x28 0xef3 0x29 0xeee 0x2b 0xee9 0x2c 0xee5 0x2d 0xee2 0x2e 0xede 0x30 0xedb 0x31 0xed9 0x32 0xed6 0x33 0xed4 0x35 0xed2 0x36 0xed0 0x37 0xece 0x38 0xecd 0x3a 0xecc 0x3b 0xecb 0x3c 0xeca 0x3d 0xeca 0x3f 0xec9 0x41 0xec7 0x42 0xec6 0x44 0xec5 0x45 0xec4 0x46 0xec2 0x47 0xec0 0x49 0xebe 0x4a 0xebc 0x4b 0xeb9 0x4c 0xeb6 0x4e 0xeb3 0x4f 0xeb0 0x50 0xeab 0x51 0xea6 0x53 0xea1 0x54 0xe9b 0x55 0xe95 0x56 0xe8e 0x58 0xe87 0x59 0xe7f 0x5a 0xe7a 0x5b 0xe77 0x5d 0xe74 0x5e 0xe71 0x5f 0xe6e 0x60 0xe67 0x62 0xe57 0x63 0xe2e 0x64 0xdef>;
			battery_profile_t1_num_1 = <0x50>;
			battery_profile_t1_1 = <0x00 0x1053 0x01 0x1024 0x02 0x100a 0x04 0xffa 0x05 0xfed 0x06 0xfe2 0x07 0xfd8 0x08 0xfcd 0x0a 0xfc4 0x0b 0xfbb 0x0c 0xfb3 0x0d 0xfaa 0x0e 0xfa2 0x0f 0xf99 0x11 0xf91 0x12 0xf8a 0x13 0xf83 0x14 0xf7c 0x15 0xf75 0x17 0xf6f 0x18 0xf67 0x19 0xf61 0x1a 0xf5b 0x1b 0xf54 0x1d 0xf4e 0x1e 0xf48 0x1f 0xf41 0x20 0xf3a 0x21 0xf34 0x23 0xf2d 0x24 0xf26 0x25 0xf1f 0x26 0xf18 0x27 0xf11 0x28 0xf0a 0x2a 0xf03 0x2b 0xefd 0x2c 0xef7 0x2d 0xef1 0x2e 0xeed 0x30 0xee8 0x31 0xee4 0x32 0xee0 0x33 0xedc 0x34 0xed9 0x36 0xed6 0x37 0xed3 0x38 0xed1 0x39 0xece 0x3a 0xecc 0x3c 0xeca 0x3e 0xec7 0x40 0xec4 0x41 0xec2 0x44 0xec0 0x46 0xebd 0x47 0xebb 0x4a 0xeb6 0x4b 0xeb3 0x4c 0xeb0 0x4d 0xeac 0x4f 0xea8 0x50 0xea3 0x51 0xe9e 0x52 0xe98 0x53 0xe92 0x55 0xe8b 0x56 0xe83 0x57 0xe7c 0x58 0xe72 0x59 0xe67 0x5a 0xe5d 0x5c 0xe57 0x5d 0xe50 0x5e 0xe49 0x5f 0xe40 0x60 0xe2c 0x62 0xdff 0x63 0xdbf 0x64 0xd67>;
			battery_profile_t1_5_num = <0x50>;
			battery_profile_t1_5 = <0x00 0x1052 0x01 0x1017 0x02 0x1008 0x03 0xffc 0x05 0xff6 0x06 0xff2 0x07 0xfec 0x08 0xfe2 0x09 0xfd0 0x0a 0xfb9 0x0c 0xfa7 0x0d 0xf9a 0x0e 0xf89 0x0f 0xf83 0x10 0xf7e 0x11 0xf7b 0x13 0xf78 0x14 0xf76 0x15 0xf71 0x16 0xf6c 0x17 0xf66 0x18 0xf60 0x1a 0xf59 0x1b 0xf53 0x1c 0xf4e 0x1d 0xf48 0x1e 0xf42 0x1f 0xf3c 0x21 0xf37 0x22 0xf31 0x23 0xf2b 0x24 0xf24 0x25 0xf1d 0x26 0xf14 0x28 0xf0a 0x29 0xf00 0x2a 0xef9 0x2b 0xef2 0x2c 0xeed 0x2d 0xee9 0x2f 0xee5 0x30 0xee1 0x31 0xede 0x32 0xedb 0x33 0xed8 0x34 0xed6 0x36 0xed3 0x37 0xed1 0x39 0xecd 0x3a 0xecb 0x3b 0xec9 0x3d 0xec8 0x3f 0xec7 0x41 0xec6 0x44 0xec4 0x46 0xec2 0x48 0xebf 0x49 0xebd 0x4b 0xeba 0x4c 0xeb7 0x4d 0xeb3 0x4e 0xeb0 0x4f 0xeac 0x50 0xea8 0x52 0xea2 0x53 0xe9c 0x54 0xe95 0x55 0xe8f 0x56 0xe88 0x57 0xe7f 0x59 0xe78 0x5a 0xe75 0x5b 0xe73 0x5d 0xe70 0x5e 0xe6d 0x60 0xe64 0x61 0xe3e 0x62 0xe03 0x63 0xdb2 0x64 0xd33>;
			battery_profile_t1_5_num_1 = <0x50>;
			battery_profile_t1_5_1 = <0x00 0x1053 0x01 0x1020 0x02 0x1011 0x04 0x1004 0x05 0xff9 0x06 0xfee 0x07 0xfe4 0x08 0xfda 0x0a 0xfd1 0x0b 0xfc8 0x0c 0xfbf 0x0d 0xfb6 0x0e 0xfae 0x0f 0xfa6 0x11 0xf9e 0x12 0xf96 0x13 0xf8f 0x14 0xf87 0x15 0xf80 0x17 0xf79 0x18 0xf72 0x19 0xf6c 0x1a 0xf65 0x1b 0xf5f 0x1d 0xf59 0x1e 0xf52 0x1f 0xf4c 0x20 0xf46 0x21 0xf40 0x23 0xf39 0x24 0xf33 0x25 0xf2c 0x26 0xf25 0x27 0xf1d 0x28 0xf16 0x2a 0xf0f 0x2b 0xf08 0x2c 0xf01 0x2d 0xefb 0x2e 0xef5 0x30 0xef0 0x31 0xeeb 0x32 0xee6 0x33 0xee3 0x34 0xedf 0x36 0xedc 0x37 0xed8 0x38 0xed6 0x39 0xed3 0x3a 0xed1 0x3c 0xece 0x3d 0xecc 0x3f 0xec8 0x41 0xec5 0x43 0xec4 0x45 0xec1 0x47 0xebe 0x4a 0xeba 0x4b 0xeb7 0x4c 0xeb3 0x4d 0xeaf 0x4f 0xeaa 0x50 0xea6 0x51 0xea2 0x52 0xe9e 0x53 0xe98 0x55 0xe92 0x56 0xe8b 0x57 0xe85 0x58 0xe7e 0x59 0xe75 0x5a 0xe6a 0x5c 0xe62 0x5d 0xe5d 0x5e 0xe57 0x5f 0xe50 0x60 0xe48 0x62 0xe33 0x63 0xe07 0x64 0xdcc>;
			battery_profile_t2_num = <0x50>;
			battery_profile_t2 = <0x00 0x1051 0x01 0x103d 0x02 0x102b 0x03 0x101f 0x04 0x1013 0x05 0x1008 0x07 0xffe 0x08 0xff4 0x09 0xfec 0x0a 0xfe7 0x0b 0xfe3 0x0c 0xfdc 0x0d 0xfcf 0x0e 0xfbb 0x0f 0xfa9 0x10 0xf9b 0x12 0xf91 0x13 0xf8a 0x14 0xf83 0x15 0xf7f 0x16 0xf7d 0x17 0xf7b 0x18 0xf76 0x19 0xf6f 0x1a 0xf68 0x1b 0xf62 0x1d 0xf5c 0x1e 0xf55 0x1f 0xf4f 0x20 0xf49 0x21 0xf44 0x22 0xf3e 0x23 0xf38 0x24 0xf33 0x25 0xf2d 0x26 0xf28 0x27 0xf21 0x29 0xf1a 0x2a 0xf11 0x2b 0xf05 0x2c 0xefb 0x2d 0xef3 0x2e 0xeed 0x2f 0xee8 0x30 0xee4 0x31 0xee0 0x32 0xedd 0x34 0xed9 0x35 0xed6 0x37 0xed1 0x39 0xecc 0x3b 0xec7 0x3d 0xec3 0x40 0xec0 0x42 0xebe 0x44 0xebc 0x46 0xeba 0x48 0xeb7 0x49 0xeb4 0x4b 0xeb1 0x4c 0xeaf 0x4d 0xeab 0x4e 0xea7 0x4f 0xea2 0x51 0xe9b 0x52 0xe97 0x53 0xe91 0x54 0xe8a 0x56 0xe84 0x57 0xe7e 0x58 0xe76 0x59 0xe6d 0x5a 0xe6a 0x5c 0xe67 0x5e 0xe64 0x5f 0xe60 0x61 0xe49 0x62 0xe19 0x63 0xdd8 0x64 0xd7a>;
			battery_profile_t2_num_1 = <0x50>;
			battery_profile_t2_1 = <0x00 0x1053 0x01 0x103d 0x02 0x102c 0x03 0x101d 0x04 0x100f 0x06 0x1004 0x07 0xff9 0x08 0xfee 0x09 0xfe5 0x0a 0xfdb 0x0b 0xfd1 0x0c 0xfc8 0x0d 0xfbf 0x0f 0xfb7 0x10 0xfae 0x11 0xfa6 0x12 0xf9e 0x13 0xf96 0x14 0xf8e 0x15 0xf87 0x16 0xf80 0x18 0xf79 0x19 0xf72 0x1a 0xf6b 0x1b 0xf64 0x1c 0xf5e 0x1d 0xf58 0x1e 0xf52 0x1f 0xf4c 0x21 0xf46 0x22 0xf40 0x23 0xf3a 0x24 0xf34 0x25 0xf2d 0x26 0xf27 0x27 0xf20 0x28 0xf19 0x2a 0xf11 0x2b 0xf09 0x2c 0xf02 0x2d 0xefa 0x2e 0xef4 0x2f 0xeef 0x30 0xee9 0x31 0xee5 0x33 0xee0 0x34 0xedc 0x36 0xed5 0x37 0xed2 0x39 0xecd 0x3c 0xec8 0x3f 0xec2 0x41 0xebe 0x43 0xebc 0x45 0xeba 0x47 0xeb7 0x49 0xeb1 0x4a 0xead 0x4b 0xea8 0x4c 0xea3 0x4e 0xe9f 0x4f 0xe9a 0x51 0xe93 0x52 0xe8e 0x53 0xe88 0x54 0xe82 0x55 0xe7a 0x57 0xe75 0x58 0xe6c 0x59 0xe64 0x5a 0xe5a 0x5b 0xe57 0x5c 0xe51 0x5d 0xe4c 0x5e 0xe44 0x60 0xe35 0x61 0xe11 0x62 0xddd 0x63 0xd9a 0x64 0xd40>;
			battery_profile_t3_num = <0x50>;
			battery_profile_t3 = <0x00 0x1053 0x01 0x102c 0x02 0x1017 0x03 0x1008 0x05 0xffc 0x06 0xff6 0x07 0xff2 0x08 0xfed 0x09 0xfe3 0x0a 0xfd0 0x0c 0xfb9 0x0d 0xfa7 0x0e 0xf9a 0x0f 0xf8a 0x10 0xf84 0x11 0xf7f 0x12 0xf7c 0x14 0xf78 0x15 0xf76 0x16 0xf72 0x17 0xf6c 0x18 0xf67 0x19 0xf60 0x1a 0xf5a 0x1c 0xf54 0x1d 0xf4e 0x1e 0xf48 0x1f 0xf43 0x20 0xf3c 0x21 0xf37 0x23 0xf32 0x24 0xf2b 0x25 0xf25 0x26 0xf1e 0x27 0xf14 0x28 0xf0a 0x29 0xf01 0x2b 0xef9 0x2c 0xef3 0x2d 0xeed 0x2e 0xee9 0x2f 0xee6 0x30 0xee2 0x32 0xede 0x33 0xedc 0x34 0xed9 0x35 0xed6 0x36 0xed4 0x37 0xed2 0x38 0xecf 0x3a 0xece 0x3b 0xecb 0x3d 0xec9 0x3f 0xec8 0x42 0xec6 0x44 0xec4 0x46 0xec2 0x49 0xec0 0x4a 0xebe 0x4b 0xebb 0x4c 0xeb7 0x4d 0xeb4 0x4e 0xeb0 0x4f 0xead 0x51 0xea8 0x52 0xea3 0x53 0xe9c 0x54 0xe96 0x55 0xe90 0x56 0xe89 0x58 0xe80 0x59 0xe78 0x5a 0xe75 0x5d 0xe71 0x5e 0xe6d 0x60 0xe64 0x61 0xe3e 0x62 0xe03 0x63 0xdb2 0x64 0xd34>;
			battery_profile_t3_num_1 = <0x50>;
			battery_profile_t3_1 = <0x00 0x1057 0x01 0x1037 0x02 0x1020 0x03 0x1011 0x05 0x1004 0x06 0xff9 0x07 0xfee 0x08 0xfe4 0x09 0xfda 0x0a 0xfd1 0x0c 0xfc8 0x0d 0xfbf 0x0e 0xfb6 0x0f 0xfae 0x10 0xfa6 0x11 0xf9e 0x13 0xf96 0x14 0xf8f 0x15 0xf87 0x16 0xf80 0x17 0xf79 0x18 0xf72 0x19 0xf6c 0x1b 0xf65 0x1c 0xf5f 0x1d 0xf59 0x1e 0xf52 0x1f 0xf4c 0x21 0xf46 0x22 0xf40 0x23 0xf39 0x24 0xf33 0x25 0xf2c 0x26 0xf25 0x28 0xf1d 0x29 0xf16 0x2a 0xf0f 0x2b 0xf08 0x2c 0xf01 0x2d 0xefb 0x2f 0xef5 0x30 0xef0 0x31 0xeeb 0x32 0xee6 0x33 0xee3 0x34 0xedf 0x37 0xed8 0x39 0xed3 0x3b 0xece 0x3e 0xeca 0x40 0xec7 0x41 0xec5 0x42 0xec4 0x45 0xec1 0x46 0xec0 0x48 0xebc 0x49 0xeba 0x4a 0xeb7 0x4c 0xeb3 0x4d 0xeaf 0x4e 0xeaa 0x4f 0xea6 0x50 0xea2 0x51 0xe9e 0x53 0xe98 0x54 0xe92 0x55 0xe8b 0x56 0xe85 0x57 0xe7e 0x58 0xe75 0x5a 0xe6a 0x5b 0xe62 0x5c 0xe5d 0x5d 0xe57 0x5e 0xe50 0x5f 0xe48 0x61 0xe33 0x62 0xe07 0x63 0xdcc 0x64 0xd7e>;
			r_profile_t0_num = <0x50>;
			r_profile_t0 = <0x143 0x1047 0x143 0x1012 0x135 0xfef 0x13f 0xfd5 0x172 0xfba 0x19d 0xf9d 0x1b4 0xf87 0x1bd 0xf7c 0x1c5 0xf76 0x1cb 0xf70 0x1d1 0xf6c 0x1d8 0xf67 0x1e0 0xf62 0x1e6 0xf5e 0x1ea 0xf58 0x1eb 0xf53 0x1ec 0xf4d 0x1ef 0xf46 0x1ee 0xf40 0x1f1 0xf39 0x1ed 0xf31 0x1ec 0xf29 0x1dd 0xf20 0x1d0 0xf18 0x1c3 0xf0f 0x1cf 0xf08 0x1c2 0xf01 0x1b7 0xefa 0x1ad 0xef4 0x1a5 0xeef 0x19c 0xeeb 0x19a 0xee7 0x1a2 0xee3 0x1a8 0xedf 0x1ad 0xedc 0x1b3 0xed9 0x1b5 0xed6 0x1b7 0xed4 0x1b9 0xed2 0x1bf 0xed0 0x1c6 0xecf 0x1cf 0xece 0x1d6 0xecc 0x1dd 0xecb 0x1e5 0xeca 0x1ec 0xec9 0x1f5 0xec7 0x1fe 0xec6 0x206 0xec4 0x20a 0xec2 0x20e 0xec0 0x213 0xebf 0x220 0xebc 0x22c 0xeba 0x236 0xeb8 0x23f 0xeb5 0x24b 0xeb2 0x256 0xeaf 0x260 0xeab 0x266 0xea8 0x26f 0xea4 0x27a 0xe9f 0x28b 0xe9b 0x24b 0xe94 0x274 0xe90 0x291 0xe8a 0x2a9 0xe84 0x2c2 0xe7f 0x2df 0xe7a 0x2fe 0xe76 0x306 0xe73 0x334 0xe6e 0x36d 0xe68 0x3bb 0xe5d 0x414 0xe45 0x47e 0xe19 0x47e 0xe19 0x47e 0xe19 0x47e 0xe19 0x47e 0xe19>;
			r_profile_t0_num_1 = <0x50>;
			r_profile_t0_1 = <0xf7 0x1043 0xf7 0x1043 0x103 0x102f 0x11d 0x1018 0x122 0xff8 0x11e 0xfe2 0x11f 0xfd4 0x123 0xfc9 0x127 0xfbe 0x12b 0xfb5 0x12e 0xfac 0x130 0xfa4 0x132 0xf9c 0x134 0xf94 0x135 0xf8c 0x138 0xf85 0x138 0xf7d 0x13a 0xf76 0x137 0xf6f 0x133 0xf68 0x130 0xf61 0x12b 0xf5a 0x127 0xf54 0x124 0xf4d 0x120 0xf46 0x11d 0xf40 0x11a 0xf39 0x118 0xf32 0x119 0xf2b 0x11b 0xf24 0x11c 0xf1d 0x11d 0xf16 0x11d 0xf0f 0x11c 0xf09 0x11c 0xf03 0x11d 0xefd 0x11f 0xef8 0x121 0xef3 0x123 0xeee 0x125 0xeea 0x127 0xee6 0x128 0xee3 0x12a 0xedf 0x12c 0xedc 0x12d 0xed9 0x12c 0xed6 0x12b 0xed4 0x12a 0xed2 0x12b 0xecf 0x12d 0xecd 0x12d 0xecc 0x12e 0xeca 0x12f 0xec6 0x12f 0xec5 0x12c 0xec1 0x12b 0xec0 0x12c 0xebe 0x114 0xebb 0x11b 0xeb9 0x11f 0xeb6 0x121 0xeb3 0x122 0xeaf 0x123 0xeab 0x123 0xea6 0x122 0xea0 0x122 0xe9a 0x123 0xe93 0x126 0xe8c 0x12a 0xe83 0x12f 0xe7a 0x135 0xe70 0x13f 0xe66 0x14e 0xe5e 0x161 0xe57 0x178 0xe4e 0x199 0xe43 0x1c6 0xe30 0x203 0xe0a 0x25f 0xdca 0x319 0xd6d>;
			r_profile_t1_num = <0x50>;
			r_profile_t1 = <0xc8 0x1044 0xc8 0x100f 0xca 0xfed 0xca 0xfd1 0xbd 0xfb5 0xb5 0xfa3 0xb3 0xf96 0xb1 0xf8c 0xb2 0xf84 0xb3 0xf7e 0xb7 0xf79 0xba 0xf75 0xbe 0xf72 0xc1 0xf6f 0xc4 0xf6b 0xc6 0xf67 0xc8 0xf62 0xc4 0xf5c 0xcc 0xf56 0xcd 0xf50 0xcd 0xf4a 0xce 0xf44 0xce 0xf3e 0xce 0xf37 0xcd 0xf31 0xcb 0xf2a 0xc8 0xf22 0xc3 0xf19 0xbe 0xf10 0xb8 0xf08 0xb4 0xf00 0xb1 0xef9 0xaf 0xef3 0xad 0xeee 0xac 0xee9 0xac 0xee5 0xac 0xee2 0xad 0xede 0xad 0xedb 0xae 0xed9 0xaf 0xed6 0xb0 0xed4 0xb1 0xed2 0xb2 0xed0 0xb4 0xece 0xb7 0xecd 0xba 0xecc 0xbd 0xecb 0xc0 0xeca 0xc4 0xeca 0xc8 0xec9 0xd1 0xec7 0xd7 0xec6 0xdc 0xec5 0xe2 0xec4 0xe3 0xec2 0xee 0xec0 0xf3 0xebe 0xd3 0xebc 0x102 0xeb9 0x10a 0xeb6 0x112 0xeb3 0x11b 0xeb0 0x124 0xeab 0x12e 0xea6 0x139 0xea1 0x144 0xe9b 0x151 0xe95 0x15d 0xe8e 0x16a 0xe87 0x178 0xe7f 0x189 0xe7a 0x1a3 0xe77 0x1c4 0xe74 0x1ef 0xe71 0x225 0xe6e 0x269 0xe67 0x2c2 0xe57 0x334 0xe2e 0x3ce 0xdef>;
			r_profile_t1_num_1 = <0x50>;
			r_profile_t1_1 = <0xc7 0x1053 0xc7 0x1024 0xbd 0x100a 0xbb 0xffa 0xbb 0xfed 0xbc 0xfe2 0xbd 0xfd8 0xbd 0xfcd 0xbf 0xfc4 0xc0 0xfbb 0xc1 0xfb3 0xc2 0xfaa 0xc3 0xfa2 0xc3 0xf99 0xc4 0xf91 0xc5 0xf8a 0xc4 0xf83 0xc7 0xf7c 0xc8 0xf75 0xc9 0xf6f 0xc9 0xf67 0xca 0xf61 0xca 0xf5b 0xca 0xf54 0xcb 0xf4e 0xcb 0xf48 0xca 0xf41 0xc9 0xf3a 0xc9 0xf34 0xc8 0xf2d 0xc7 0xf26 0xc5 0xf1f 0xc4 0xf18 0xc2 0xf11 0xbf 0xf0a 0xbd 0xf03 0xbc 0xefd 0xbb 0xef7 0xba 0xef1 0xb9 0xeed 0xba 0xee8 0xb9 0xee4 0xba 0xee0 0xb9 0xedc 0xba 0xed9 0xbb 0xed6 0xbc 0xed3 0xbc 0xed1 0xbc 0xece 0xbc 0xecc 0xbc 0xeca 0xbd 0xec7 0xbe 0xec4 0xbc 0xec2 0xc0 0xec0 0xc1 0xebd 0xc1 0xebb 0xc2 0xeb6 0xc3 0xeb3 0xc3 0xeb0 0xc4 0xeac 0xc4 0xea8 0xc4 0xea3 0xc6 0xe9e 0xc7 0xe98 0xc9 0xe92 0xcb 0xe8b 0xcd 0xe83 0xd1 0xe7c 0xd2 0xe72 0xd2 0xe67 0xd4 0xe5d 0xde 0xe57 0xea 0xe50 0xfa 0xe49 0x112 0xe40 0x139 0xe2c 0x166 0xdff 0x1a5 0xdbf 0x216 0xd67>;
			r_profile_t1_5_num = <0x50>;
			r_profile_t1_5 = <0xf8 0x1052 0xf8 0x1017 0xfb 0x1008 0xfd 0xffc 0x102 0xff6 0x109 0xff2 0x10f 0xfec 0x110 0xfe2 0x10b 0xfd0 0x105 0xfb9 0x103 0xfa7 0x103 0xf9a 0xf8 0xf89 0xfa 0xf83 0xfe 0xf7e 0x102 0xf7b 0x107 0xf78 0x10a 0xf76 0x10b 0xf71 0x109 0xf6c 0x108 0xf66 0x108 0xf60 0x109 0xf59 0x10a 0xf53 0x10c 0xf4e 0x10d 0xf48 0x10f 0xf42 0x10f 0xf3c 0x110 0xf37 0x111 0xf31 0x111 0xf2b 0x10f 0xf24 0x10c 0xf1d 0x107 0xf14 0xff 0xf0a 0xf8 0xf00 0xf5 0xef9 0xf2 0xef2 0xf1 0xeed 0xf1 0xee9 0xf1 0xee5 0xf1 0xee1 0xf1 0xede 0xf2 0xedb 0xf2 0xed8 0xf3 0xed6 0xf4 0xed3 0xf5 0xed1 0xf6 0xecd 0xf7 0xecb 0xf8 0xec9 0xf9 0xec8 0xfc 0xec7 0xfe 0xec6 0x100 0xec4 0x103 0xec2 0x105 0xebf 0x105 0xebd 0x105 0xeba 0x105 0xeb7 0x105 0xeb3 0x106 0xeb0 0x108 0xeac 0x10a 0xea8 0x10a 0xea2 0x10a 0xe9c 0x10c 0xe95 0x110 0xe8f 0x113 0xe88 0x113 0xe7f 0x11a 0xe78 0x125 0xe75 0x12c 0xe73 0x141 0xe70 0x14f 0xe6d 0x15b 0xe64 0x145 0xe3e 0x12c 0xe03 0x125 0xdb2 0x10c 0xd33>;
			r_profile_t1_5_num_1 = <0x50>;
			r_profile_t1_5_1 = <0x94 0x1053 0x94 0x1020 0x92 0x1011 0x90 0x1004 0x91 0xff9 0x91 0xfee 0x92 0xfe4 0x92 0xfda 0x93 0xfd1 0x93 0xfc8 0x94 0xfbf 0x95 0xfb6 0x96 0xfae 0x96 0xfa6 0xa4 0xf9e 0xa5 0xf96 0xa5 0xf8f 0xa5 0xf87 0xa5 0xf80 0xa6 0xf79 0xa6 0xf72 0xa7 0xf6c 0xa7 0xf65 0xa7 0xf5f 0xa7 0xf59 0xa7 0xf52 0xa7 0xf4c 0xa7 0xf46 0xa7 0xf40 0xa6 0xf39 0xa6 0xf33 0xa5 0xf2c 0xa3 0xf25 0xa1 0xf1d 0x9f 0xf16 0x9c 0xf0f 0x99 0xf08 0x97 0xf01 0x95 0xefb 0x93 0xef5 0x91 0xef0 0x90 0xeeb 0x8f 0xee6 0x8f 0xee3 0x8e 0xedf 0x8e 0xedc 0x8e 0xed8 0x8f 0xed6 0x8e 0xed3 0x8e 0xed1 0x8f 0xece 0x8f 0xecc 0x8f 0xec8 0x8f 0xec5 0x8e 0xec4 0x90 0xec1 0x91 0xebe 0x93 0xeba 0x94 0xeb7 0x95 0xeb3 0x94 0xeaf 0x94 0xeaa 0x95 0xea6 0x97 0xea2 0x9a 0xe9e 0x9c 0xe98 0x9e 0xe92 0xa0 0xe8b 0xa3 0xe85 0xa8 0xe7e 0xa7 0xe75 0xa2 0xe6a 0xa3 0xe62 0xab 0xe5d 0xb7 0xe57 0xcd 0xe50 0x103 0xe48 0x148 0xe33 0x189 0xe07 0x1f4 0xdcc>;
			r_profile_t2_num = <0x50>;
			r_profile_t2 = <0x63 0x1051 0x63 0x103d 0x58 0x102b 0x5a 0x101f 0x5a 0x1013 0x5c 0x1008 0x5c 0xffe 0x58 0xff4 0x5a 0xfec 0x5c 0xfe7 0x60 0xfe3 0x6a 0xfdc 0x6c 0xfcf 0x6a 0xfbb 0x65 0xfa9 0x5d 0xf9b 0x57 0xf91 0x54 0xf8a 0x56 0xf83 0x56 0xf7f 0x58 0xf7d 0x5a 0xf7b 0x5c 0xf76 0x5e 0xf6f 0x60 0xf68 0x62 0xf62 0x65 0xf5c 0x65 0xf55 0x65 0xf4f 0x67 0xf49 0x6a 0xf44 0x6a 0xf3e 0x6c 0xf38 0x6e 0xf33 0x70 0xf2d 0x70 0xf28 0x70 0xf21 0x6f 0xf1a 0x68 0xf11 0x61 0xf05 0x58 0xefb 0x51 0xef3 0x50 0xeed 0x4d 0xee8 0x49 0xee4 0x4d 0xee0 0x49 0xedd 0x4c 0xed9 0x49 0xed6 0x4c 0xed1 0x4c 0xecc 0x4c 0xec7 0x4a 0xec3 0x4a 0xec0 0x4a 0xebe 0x4c 0xebc 0x4d 0xeba 0x4e 0xeb7 0x4f 0xeb4 0x4e 0xeb1 0x50 0xeaf 0x51 0xeab 0x51 0xea7 0x4c 0xea2 0x52 0xe9b 0x54 0xe97 0x58 0xe91 0x57 0xe8a 0x58 0xe84 0x5b 0xe7e 0x5e 0xe76 0x51 0xe6d 0x52 0xe6a 0x54 0xe67 0x63 0xe64 0x85 0xe60 0xb5 0xe49 0xdf 0xe19 0x11f 0xdd8 0x1b2 0xd7a>;
			r_profile_t2_num_1 = <0x50>;
			r_profile_t2_1 = <0x7e 0x1053 0x7e 0x103d 0x7d 0x102c 0x79 0x101d 0x77 0x100f 0x78 0x1004 0x76 0xff9 0x76 0xfee 0x78 0xfe5 0x77 0xfdb 0x77 0xfd1 0x78 0xfc8 0x76 0xfbf 0x79 0xfb7 0x78 0xfae 0x78 0xfa6 0x79 0xf9e 0x79 0xf96 0x78 0xf8e 0x78 0xf87 0x7a 0xf80 0x7b 0xf79 0x7b 0xf72 0x7b 0xf6b 0x7b 0xf64 0x7c 0xf5e 0x7d 0xf58 0x7f 0xf52 0x80 0xf4c 0x80 0xf46 0x80 0xf40 0x81 0xf3a 0x80 0xf34 0x81 0xf2d 0x80 0xf27 0x80 0xf20 0x7e 0xf19 0x7b 0xf11 0x78 0xf09 0x77 0xf02 0x72 0xefa 0x72 0xef4 0x71 0xeef 0x6e 0xee9 0x6f 0xee5 0x6c 0xee0 0x6d 0xedc 0x6d 0xed5 0x6c 0xed2 0x6e 0xecd 0x6e 0xec8 0x6f 0xec2 0x6e 0xebe 0x6f 0xebc 0x6f 0xeba 0x70 0xeb7 0x70 0xeb1 0x70 0xead 0x6f 0xea8 0x6f 0xea3 0x6f 0xe9f 0x6e 0xe9a 0x71 0xe93 0x72 0xe8e 0x72 0xe88 0x74 0xe82 0x72 0xe7a 0x76 0xe75 0x78 0xe6c 0x78 0xe64 0x71 0xe5a 0x76 0xe57 0x76 0xe51 0x7f 0xe4c 0x89 0xe44 0xaa 0xe35 0xc5 0xe11 0xe2 0xddd 0x110 0xd9a 0x17e 0xd40>;
			r_profile_t3_num = <0x50>;
			r_profile_t3 = <0x85 0x1053 0x85 0x102c 0x7f 0x1017 0x7a 0x1008 0x76 0xffc 0x7a 0xff6 0x81 0xff2 0x8a 0xfed 0x94 0xfe3 0x96 0xfd0 0x8b 0xfb9 0x81 0xfa7 0x7d 0xf9a 0x6e 0xf8a 0x6f 0xf84 0x72 0xf7f 0x76 0xf7c 0x78 0xf78 0x7c 0xf76 0x7b 0xf72 0x7b 0xf6c 0x7e 0xf67 0x7e 0xf60 0x7e 0xf5a 0x80 0xf54 0x81 0xf4e 0x81 0xf48 0x83 0xf43 0x83 0xf3c 0x83 0xf37 0x85 0xf32 0x83 0xf2b 0x83 0xf25 0x80 0xf1e 0x7a 0xf14 0x73 0xf0a 0x94 0xf01 0x8e 0xef9 0x8b 0xef3 0x8a 0xeed 0xbb 0xee9 0xbb 0xee6 0xba 0xee2 0x10b 0xede 0x10b 0xedc 0x10c 0xed9 0x10b 0xed6 0x10c 0xed4 0x10e 0xed2 0x10d 0xecf 0x10f 0xece 0x10f 0xecb 0x110 0xec9 0x112 0xec8 0x113 0xec6 0x116 0xec4 0x119 0xec2 0x11d 0xec0 0x11f 0xebe 0x11e 0xebb 0x11f 0xeb7 0x103 0xeb4 0x103 0xeb0 0x107 0xead 0xb9 0xea8 0xbb 0xea3 0xbd 0xe9c 0xc0 0xe96 0xc5 0xe90 0xca 0xe89 0xcc 0xe80 0xce 0xe78 0xd5 0xe75 0xc0 0xe71 0xd4 0xe6d 0xee 0xe64 0xf7 0xe3e 0x116 0xe03 0x149 0xdb2 0x19d 0xd34>;
			r_profile_t3_num_1 = <0x50>;
			r_profile_t3_1 = <0x9d 0x1057 0x9d 0x1037 0x94 0x1020 0x92 0x1011 0x90 0x1004 0x91 0xff9 0x91 0xfee 0x92 0xfe4 0x92 0xfda 0x93 0xfd1 0x93 0xfc8 0x94 0xfbf 0x95 0xfb6 0x96 0xfae 0x96 0xfa6 0xa4 0xf9e 0xa5 0xf96 0xa5 0xf8f 0xa5 0xf87 0xa5 0xf80 0xa6 0xf79 0xa6 0xf72 0xa7 0xf6c 0xa7 0xf65 0xa7 0xf5f 0xa7 0xf59 0xa7 0xf52 0xa7 0xf4c 0xa7 0xf46 0xa7 0xf40 0xa6 0xf39 0xa6 0xf33 0xa5 0xf2c 0xa3 0xf25 0xa1 0xf1d 0x9f 0xf16 0x9c 0xf0f 0x99 0xf08 0x97 0xf01 0x95 0xefb 0x93 0xef5 0x91 0xef0 0x90 0xeeb 0x8f 0xee6 0x8f 0xee3 0x8e 0xedf 0x8e 0xed8 0x8e 0xed3 0x8f 0xece 0x8e 0xeca 0x8e 0xec7 0x8f 0xec5 0x8e 0xec4 0x90 0xec1 0x91 0xec0 0x92 0xebc 0x93 0xeba 0x94 0xeb7 0x95 0xeb3 0x94 0xeaf 0x94 0xeaa 0x95 0xea6 0x97 0xea2 0x9a 0xe9e 0x9c 0xe98 0x9e 0xe92 0xa0 0xe8b 0xa3 0xe85 0xa8 0xe7e 0xa7 0xe75 0xa2 0xe6a 0xa3 0xe62 0xab 0xe5d 0xb7 0xe57 0xcd 0xe50 0x103 0xe48 0x148 0xe33 0x189 0xe07 0x1f4 0xdcc 0x32d 0xd7e>;
			r_profile_t4 = <0x85 0x1053 0x85 0x102c 0x7f 0x1017 0x7a 0x1008 0x76 0xffc 0x7a 0xff6 0x81 0xff2 0x8a 0xfed 0x94 0xfe3 0x96 0xfd0 0x8b 0xfb9 0x81 0xfa7 0x7d 0xf9a 0x6e 0xf8a 0x6f 0xf84 0x72 0xf7f 0x76 0xf7c 0x78 0xf78 0x7c 0xf76 0x7b 0xf72 0x7b 0xf6c 0x7e 0xf67 0x7e 0xf60 0x7e 0xf5a 0x80 0xf54 0x81 0xf4e 0x81 0xf48 0x83 0xf43 0x83 0xf3c 0x83 0xf37 0x85 0xf32 0x83 0xf2b 0x83 0xf25 0x80 0xf1e 0x7a 0xf14 0x73 0xf0a 0x94 0xf01 0x6d 0xef9 0x72 0xef3 0x6e 0xeed 0x72 0xee9 0x73 0xee6 0x75 0xee2 0x76 0xede 0x80 0xedc 0x7b 0xed9 0x82 0xed6 0x80 0xed4 0x8a 0xed2 0x86 0xecf 0x8a 0xece 0x8a 0xecb 0x84 0xec9 0x82 0xec8 0x8d 0xec6 0x87 0xec4 0x8b 0xec2 0x95 0xec0 0x9f 0xebe 0x6b 0xebb 0x83 0xeb7 0x9e 0xeb4 0x9e 0xeb0 0x91 0xead 0x81 0xea8 0x88 0xea3 0xa6 0xe9c 0xac 0xe96 0xb1 0xe90 0xb6 0xe89 0x89 0xe80 0x82 0xe78 0xd5 0xe75 0xc0 0xe71 0xd4 0xe6d 0xee 0xe64 0xf7 0xe3e 0x116 0xe03 0x149 0xdb2 0x19d 0xd34>;
			battery_profile_t1_500cycle = <0x00 0x1067 0x01 0x1059 0x02 0x104c 0x04 0x1041 0x05 0x1036 0x06 0x102b 0x07 0x1022 0x08 0x1018 0x09 0x1010 0x0b 0x100c 0x0c 0x1009 0x0d 0x1004 0x0e 0xff9 0x0f 0xfe5 0x10 0xfca 0x12 0xfb4 0x13 0xfa6 0x14 0xf9b 0x15 0xf93 0x16 0xf8c 0x18 0xf86 0x19 0xf81 0x1a 0xf7d 0x1b 0xf7b 0x1c 0xf78 0x1d 0xf74 0x1f 0xf6f 0x20 0xf68 0x21 0xf62 0x22 0xf5b 0x23 0xf54 0x25 0xf4b 0x26 0xf42 0x27 0xf37 0x28 0xf2c 0x29 0xf22 0x2a 0xf19 0x2c 0xf11 0x2d 0xf0a 0x2e 0xf04 0x2f 0xeff 0x30 0xefb 0x31 0xef7 0x33 0xef3 0x34 0xeef 0x35 0xeeb 0x36 0xee8 0x37 0xee5 0x39 0xee2 0x3a 0xedf 0x3b 0xedd 0x3c 0xeda 0x3e 0xed7 0x41 0xed5 0x43 0xed0 0x46 0xeca 0x48 0xec3 0x4a 0xeb6 0x4b 0xec7 0x4d 0xec3 0x4e 0xebe 0x4f 0xeba 0x50 0xeb6 0x51 0xeb2 0x52 0xead 0x54 0xea7 0x55 0xea0 0x56 0xe98 0x57 0xe90 0x58 0xe88 0x5a 0xe83 0x5b 0xe7f 0x5c 0xe7c 0x5d 0xe78 0x5e 0xe73 0x5f 0xe68 0x61 0xe4a 0x62 0xe11 0x63 0xdbd 0x64 0xd35>;
			battery_profile_t1_5_500cycle = <0x00 0x1066 0x01 0x105c 0x02 0x1051 0x04 0x1046 0x05 0x103c 0x06 0x1031 0x07 0x1027 0x08 0x101d 0x09 0x1014 0x0b 0x100b 0x0c 0x1007 0x0d 0x1005 0x0e 0x1000 0x0f 0xff5 0x10 0xfe0 0x12 0xfc8 0x13 0xfb4 0x14 0xfa7 0x15 0xf9c 0x16 0xf94 0x17 0xf8e 0x19 0xf88 0x1a 0xf84 0x1b 0xf82 0x1c 0xf7f 0x1d 0xf7b 0x1e 0xf76 0x20 0xf70 0x21 0xf6a 0x22 0xf64 0x23 0xf5d 0x24 0xf56 0x25 0xf4f 0x27 0xf46 0x28 0xf3b 0x29 0xf30 0x2a 0xf24 0x2b 0xf1b 0x2c 0xf13 0x2e 0xf0c 0x2f 0xf06 0x30 0xf01 0x31 0xefc 0x32 0xef8 0x33 0xef4 0x35 0xef0 0x36 0xeed 0x37 0xeea 0x39 0xee4 0x3a 0xee1 0x3c 0xede 0x3d 0xedb 0x3f 0xed6 0x42 0xed3 0x44 0xed0 0x46 0xecd 0x49 0xec9 0x4a 0xec6 0x4b 0xec3 0x4c 0xebe 0x4d 0xeba 0x4e 0xeb6 0x50 0xeb2 0x51 0xeae 0x52 0xeaa 0x53 0xea4 0x54 0xe9e 0x55 0xe97 0x57 0xe8f 0x58 0xe87 0x59 0xe80 0x5a 0xe7b 0x5b 0xe78 0x5e 0xe73 0x5f 0xe6c 0x60 0xe5b 0x61 0xe32 0x62 0xdf2 0x63 0xd94 0x64 0xcf4>;
			battery_profile_t2_500cycle = <0x00 0x1051 0x01 0x1044 0x02 0x1038 0x04 0x102d 0x05 0x1023 0x06 0x1018 0x07 0x100e 0x08 0x1004 0x0a 0xffa 0x0b 0xff1 0x0c 0xfeb 0x0d 0xfe8 0x0e 0xfe5 0x0f 0xfda 0x11 0xfc8 0x12 0xfb2 0x13 0xfa1 0x14 0xf94 0x15 0xf8b 0x17 0xf84 0x18 0xf7e 0x19 0xf7a 0x1a 0xf78 0x1b 0xf75 0x1d 0xf6f 0x1e 0xf69 0x1f 0xf62 0x20 0xf5c 0x21 0xf55 0x22 0xf4f 0x24 0xf49 0x25 0xf42 0x26 0xf3a 0x27 0xf32 0x28 0xf27 0x2a 0xf1a 0x2b 0xf0f 0x2c 0xf06 0x2d 0xefe 0x2e 0xef8 0x30 0xef3 0x31 0xeee 0x32 0xeea 0x33 0xee5 0x34 0xee1 0x35 0xedd 0x37 0xeda 0x38 0xed7 0x39 0xed3 0x3b 0xece 0x3e 0xec8 0x40 0xec3 0x43 0xebe 0x45 0xeba 0x46 0xeb6 0x47 0xeb4 0x48 0xeb0 0x4a 0xeab 0x4b 0xea7 0x4c 0xea2 0x4d 0xe9d 0x4e 0xe99 0x50 0xe96 0x51 0xe93 0x52 0xe8f 0x53 0xe89 0x54 0xe82 0x56 0xe7c 0x57 0xe74 0x58 0xe6b 0x59 0xe64 0x5a 0xe61 0x5b 0xe60 0x5d 0xe5e 0x5e 0xe5c 0x5f 0xe57 0x60 0xe42 0x61 0xe10 0x63 0xdca 0x64 0xd65>;
			battery_profile_t3_500cycle = <0x00 0x104f 0x01 0x1043 0x02 0x1038 0x04 0x102e 0x05 0x1023 0x06 0x1019 0x07 0x100f 0x08 0x1005 0x09 0xffb 0x0b 0xff1 0x0c 0xfe8 0x0d 0xfe0 0x0e 0xfdb 0x0f 0xfd3 0x11 0xfc5 0x12 0xfb7 0x13 0xfac 0x14 0xfa5 0x15 0xfa0 0x17 0xf99 0x18 0xf92 0x19 0xf8a 0x1a 0xf83 0x1b 0xf7c 0x1c 0xf74 0x1e 0xf6e 0x1f 0xf67 0x20 0xf60 0x21 0xf5a 0x22 0xf54 0x24 0xf4d 0x25 0xf46 0x26 0xf3f 0x27 0xf36 0x28 0xf2c 0x2a 0xf20 0x2b 0xf15 0x2c 0xf0c 0x2d 0xf05 0x2e 0xf00 0x2f 0xefa 0x31 0xef6 0x32 0xef1 0x33 0xeed 0x34 0xee9 0x35 0xee5 0x37 0xee2 0x38 0xede 0x39 0xedb 0x3a 0xed8 0x3b 0xed4 0x3d 0xed1 0x3f 0xecc 0x41 0xec7 0x44 0xec2 0x46 0xeba 0x48 0xeab 0x4a 0xea4 0x4b 0xe9f 0x4c 0xe9b 0x4d 0xe95 0x4e 0xe91 0x4f 0xe8e 0x51 0xe8a 0x52 0xe87 0x53 0xe82 0x54 0xe7b 0x55 0xe75 0x57 0xe6e 0x58 0xe65 0x59 0xe5e 0x5a 0xe5c 0x5b 0xe5a 0x5d 0xe59 0x5e 0xe57 0x5f 0xe52 0x60 0xe3e 0x61 0xe0e 0x62 0xdcd 0x64 0xd72>;
			r_profile_t1_500cycle = <0x124 0x1067 0x123 0x1059 0x125 0x104c 0x126 0x1041 0x128 0x1036 0x128 0x102b 0x12a 0x1022 0x128 0x1018 0x129 0x1010 0x130 0x100c 0x13e 0x1009 0x149 0x1004 0x14e 0xff9 0x14a 0xfe5 0x13d 0xfca 0x138 0xfb4 0x139 0xfa6 0x139 0xf9b 0x13d 0xf93 0x13e 0xf8c 0x141 0xf86 0x143 0xf81 0x147 0xf7d 0x14d 0xf7b 0x152 0xf78 0x155 0xf74 0x157 0xf6f 0x158 0xf68 0x15a 0xf62 0x15c 0xf5b 0x15b 0xf54 0x15b 0xf4b 0x157 0xf42 0x151 0xf37 0x14d 0xf2c 0x148 0xf22 0x143 0xf19 0x143 0xf11 0x143 0xf0a 0x140 0xf04 0x143 0xeff 0x145 0xefb 0x148 0xef7 0x148 0xef3 0x14c 0xeef 0x14d 0xeeb 0x150 0xee8 0x154 0xee5 0x158 0xee2 0x15a 0xedf 0x15d 0xedd 0x15f 0xeda 0x167 0xed7 0x16c 0xed5 0x79 0xed0 0x77 0xeca 0x77 0xec3 0x72 0xeb6 0x122 0xec7 0x182 0xec3 0x187 0xebe 0x18e 0xeba 0x194 0xeb6 0x19a 0xeb2 0x1a0 0xead 0x1a8 0xea7 0x1af 0xea0 0x1b7 0xe98 0x1bf 0xe90 0x1c8 0xe88 0x1d2 0xe83 0x1e5 0xe7f 0x1fd 0xe7c 0x21b 0xe78 0x243 0xe73 0x26f 0xe68 0x29b 0xe4a 0x2d3 0xe11 0x32a 0xdbd 0x3b9 0xd35>;
			r_profile_t1_5_500cycle = <0xc9 0x1066 0xc9 0x105c 0xca 0x1051 0xcb 0x1046 0xcb 0x103c 0xcc 0x1031 0xcc 0x1027 0xcd 0x101d 0xcb 0x1014 0xc9 0x100b 0xcc 0x1007 0xd6 0x1005 0xdf 0x1000 0xe1 0xff5 0xde 0xfe0 0xd7 0xfc8 0xd3 0xfb4 0xd3 0xfa7 0xd2 0xf9c 0xd4 0xf94 0xd4 0xf8e 0xd6 0xf88 0xd8 0xf84 0xdc 0xf82 0xe1 0xf7f 0xe4 0xf7b 0xe6 0xf76 0xe8 0xf70 0xea 0xf6a 0xec 0xf64 0xee 0xf5d 0xf1 0xf56 0xf1 0xf4f 0xf0 0xf46 0xec 0xf3b 0xe5 0xf30 0xdf 0xf24 0xda 0xf1b 0xd8 0xf13 0xd5 0xf0c 0xd5 0xf06 0xd4 0xf01 0xd5 0xefc 0xd5 0xef8 0xd6 0xef4 0xd7 0xef0 0xd8 0xeed 0xd9 0xeea 0xdc 0xee4 0xdd 0xee1 0xde 0xede 0xe0 0xedb 0xe3 0xed6 0xe5 0xed3 0xe9 0xed0 0xeb 0xecd 0xed 0xec9 0xee 0xec6 0xee 0xec3 0xef 0xebe 0xf0 0xeba 0xf1 0xeb6 0xf5 0xeb2 0xf8 0xeae 0xfd 0xeaa 0xfe 0xea4 0x103 0xe9e 0x107 0xe97 0x10c 0xe8f 0x10f 0xe87 0x114 0xe80 0x119 0xe7b 0x124 0xe78 0x145 0xe73 0x15e 0xe6c 0x17c 0xe5b 0x194 0xe32 0x1b4 0xdf2 0x1ef 0xd94 0x284 0xcf4>;
			r_profile_t2_500cycle = <0x75 0x1051 0x75 0x1044 0x77 0x1038 0x78 0x102d 0x79 0x1023 0x78 0x1018 0x78 0x100e 0x78 0x1004 0x79 0xffa 0x78 0xff1 0x77 0xfeb 0x7a 0xfe8 0x7e 0xfe5 0x7e 0xfda 0x7c 0xfc8 0x7b 0xfb2 0x7b 0xfa1 0x7a 0xf94 0x7a 0xf8b 0x7b 0xf84 0x79 0xf7e 0x7b 0xf7a 0x7e 0xf78 0x80 0xf75 0x7f 0xf6f 0x81 0xf69 0x82 0xf62 0x84 0xf5c 0x85 0xf55 0x87 0xf4f 0x8b 0xf49 0x8e 0xf42 0x8f 0xf3a 0x90 0xf32 0x8e 0xf27 0x88 0xf1a 0x84 0xf0f 0x80 0xf06 0x7e 0xefe 0x7e 0xef8 0x7d 0xef3 0x7c 0xeee 0x79 0xeea 0x79 0xee5 0x79 0xee1 0x79 0xedd 0x7a 0xeda 0x80 0xed7 0x80 0xed3 0x82 0xece 0x82 0xec8 0x83 0xec3 0x85 0xebe 0x85 0xeba 0x84 0xeb6 0x84 0xeb4 0x83 0xeb0 0x81 0xeab 0x81 0xea7 0x80 0xea2 0x80 0xe9d 0x80 0xe99 0x81 0xe96 0x82 0xe93 0x84 0xe8f 0x84 0xe89 0x83 0xe82 0x83 0xe7c 0x83 0xe74 0x82 0xe6b 0x81 0xe64 0x81 0xe61 0x83 0xe60 0x85 0xe5e 0x89 0xe5c 0x90 0xe57 0x93 0xe42 0x90 0xe10 0x92 0xdca 0x9b 0xd65>;
			r_profile_t3_500cycle = <0x65 0x104f 0x65 0x1043 0x65 0x1038 0x65 0x102e 0x65 0x1023 0x65 0x1019 0x65 0x100f 0x66 0x1005 0x65 0xffb 0x65 0xff1 0x66 0xfe8 0x67 0xfe0 0x68 0xfdb 0x68 0xfd3 0x67 0xfc5 0x67 0xfb7 0x67 0xfac 0x68 0xfa5 0x68 0xfa0 0x68 0xf99 0x68 0xf92 0x68 0xf8a 0x69 0xf83 0x6a 0xf7c 0x6b 0xf74 0x6c 0xf6e 0x6d 0xf67 0x6d 0xf60 0x6e 0xf5a 0x70 0xf54 0x70 0xf4d 0x73 0xf46 0x74 0xf3f 0x75 0xf36 0x74 0xf2c 0x70 0xf20 0x6d 0xf15 0x6b 0xf0c 0x69 0xf05 0x69 0xf00 0x68 0xefa 0x67 0xef6 0x68 0xef1 0x67 0xeed 0x67 0xee9 0x67 0xee5 0x68 0xee2 0x69 0xede 0x69 0xedb 0x69 0xed8 0x69 0xed4 0x6a 0xed1 0x6b 0xecc 0x6c 0xec7 0x6e 0xec2 0x6d 0xeba 0x67 0xeab 0x67 0xea4 0x68 0xe9f 0x68 0xe9b 0x68 0xe95 0x67 0xe91 0x69 0xe8e 0x68 0xe8a 0x69 0xe87 0x69 0xe82 0x69 0xe7b 0x69 0xe75 0x68 0xe6e 0x69 0xe65 0x67 0xe5e 0x68 0xe5c 0x68 0xe5a 0x6b 0xe59 0x6c 0xe57 0x70 0xe52 0x6d 0xe3e 0x6d 0xe0e 0x71 0xdcd 0x79 0xd72>;
			battery_profile_t1_500cycle_1 = <0x00 0x1060 0x01 0x105b 0x02 0x104d 0x04 0x1041 0x05 0x1036 0x06 0x102b 0x07 0x1020 0x08 0x1016 0x09 0x100b 0x0b 0x1002 0x0c 0xff8 0x0d 0xfee 0x0e 0xfe5 0x0f 0xfdc 0x11 0xfd3 0x12 0xfca 0x13 0xfc1 0x14 0xfb9 0x15 0xfb0 0x17 0xfa9 0x18 0xfa0 0x19 0xf99 0x1a 0xf91 0x1b 0xf8a 0x1c 0xf83 0x1e 0xf7c 0x1f 0xf75 0x20 0xf6e 0x21 0xf67 0x22 0xf5f 0x24 0xf58 0x25 0xf51 0x26 0xf49 0x27 0xf40 0x28 0xf38 0x29 0xf2f 0x2b 0xf26 0x2c 0xf1e 0x2d 0xf17 0x2e 0xf10 0x2f 0xf09 0x31 0xf03 0x32 0xefe 0x33 0xef9 0x34 0xef5 0x35 0xef0 0x36 0xeed 0x38 0xee9 0x39 0xee6 0x3a 0xee2 0x3b 0xedf 0x3e 0xed9 0x40 0xed5 0x41 0xed2 0x44 0xece 0x46 0xeca 0x47 0xec8 0x49 0xec3 0x4b 0xec0 0x4c 0xebb 0x4d 0xeb6 0x4e 0xeb1 0x4f 0xead 0x51 0xea9 0x52 0xea4 0x53 0xe9e 0x54 0xe98 0x55 0xe91 0x56 0xe8a 0x58 0xe82 0x59 0xe78 0x5a 0xe71 0x5b 0xe6b 0x5c 0xe66 0x5e 0xe5f 0x5f 0xe54 0x60 0xe40 0x61 0xe13 0x62 0xdd3 0x64 0xd7d>;
			battery_profile_t1_5_500cycle_1 = <0x00 0x105c 0x01 0x104e 0x02 0x1042 0x04 0x1037 0x05 0x102b 0x06 0x1021 0x07 0x1016 0x08 0x100c 0x0a 0x1002 0x0b 0xff9 0x0c 0xfef 0x0d 0xfe5 0x0e 0xfdc 0x10 0xfd3 0x11 0xfca 0x12 0xfc2 0x13 0xfba 0x14 0xfb1 0x16 0xfa9 0x17 0xfa1 0x18 0xf9a 0x19 0xf93 0x1a 0xf8b 0x1c 0xf84 0x1d 0xf7d 0x1e 0xf76 0x1f 0xf70 0x20 0xf69 0x22 0xf62 0x23 0xf5c 0x24 0xf55 0x25 0xf4e 0x26 0xf46 0x28 0xf3d 0x29 0xf33 0x2a 0xf2a 0x2b 0xf20 0x2c 0xf18 0x2e 0xf11 0x2f 0xf0b 0x30 0xf05 0x31 0xf00 0x32 0xefb 0x34 0xef6 0x35 0xef2 0x36 0xeee 0x37 0xeeb 0x38 0xee7 0x3a 0xee4 0x3b 0xee1 0x3c 0xede 0x3d 0xedb 0x40 0xed6 0x42 0xed1 0x43 0xecf 0x46 0xecb 0x48 0xec6 0x49 0xec2 0x4a 0xebd 0x4c 0xeb7 0x4d 0xeb1 0x4e 0xead 0x4f 0xea9 0x50 0xea5 0x52 0xea1 0x53 0xe9c 0x54 0xe96 0x55 0xe8f 0x56 0xe89 0x57 0xe80 0x59 0xe77 0x5a 0xe70 0x5b 0xe6c 0x5c 0xe67 0x5d 0xe61 0x5f 0xe58 0x60 0xe42 0x61 0xe14 0x62 0xdd5 0x64 0xd80>;
			battery_profile_t2_500cycle_1 = <0x00 0x1054 0x01 0x1044 0x02 0x1036 0x04 0x1029 0x05 0x101d 0x06 0x1012 0x07 0x1007 0x08 0xffc 0x0a 0xff2 0x0b 0xfe8 0x0c 0xfdf 0x0d 0xfd5 0x0e 0xfcc 0x10 0xfc3 0x11 0xfbb 0x12 0xfb1 0x13 0xfa9 0x14 0xfa0 0x16 0xf99 0x17 0xf90 0x18 0xf89 0x19 0xf82 0x1a 0xf7b 0x1c 0xf74 0x1d 0xf6c 0x1e 0xf66 0x1f 0xf5e 0x20 0xf58 0x22 0xf51 0x23 0xf4b 0x24 0xf44 0x25 0xf3e 0x26 0xf37 0x28 0xf30 0x29 0xf28 0x2a 0xf1f 0x2b 0xf15 0x2c 0xf0c 0x2d 0xf04 0x2f 0xeff 0x30 0xef8 0x31 0xef3 0x32 0xeed 0x33 0xee8 0x35 0xee4 0x36 0xee0 0x37 0xedc 0x39 0xed5 0x3b 0xed1 0x3d 0xecb 0x3f 0xec6 0x42 0xec1 0x43 0xebe 0x44 0xebc 0x45 0xeba 0x47 0xeb6 0x48 0xeb2 0x49 0xead 0x4a 0xea6 0x4b 0xea0 0x4d 0xe9b 0x4e 0xe96 0x4f 0xe92 0x50 0xe8e 0x51 0xe8a 0x53 0xe85 0x54 0xe80 0x55 0xe7a 0x56 0xe73 0x57 0xe6c 0x59 0xe62 0x5a 0xe5c 0x5b 0xe58 0x5c 0xe53 0x5d 0xe4e 0x5f 0xe45 0x60 0xe33 0x61 0xe09 0x62 0xdcf 0x64 0xd82>;
			battery_profile_t3_500cycle_1 = <0x00 0x1057 0x01 0x104a 0x02 0x103d 0x04 0x1032 0x05 0x1027 0x06 0x101c 0x07 0x1012 0x08 0x1007 0x0a 0xffe 0x0b 0xff4 0x0c 0xfea 0x0d 0xfe1 0x0e 0xfd8 0x10 0xfcf 0x11 0xfc6 0x12 0xfbe 0x13 0xfb5 0x14 0xfad 0x16 0xfa5 0x17 0xf9d 0x18 0xf95 0x19 0xf8e 0x1a 0xf86 0x1c 0xf7f 0x1d 0xf78 0x1e 0xf71 0x1f 0xf6b 0x20 0xf64 0x22 0xf5e 0x23 0xf57 0x24 0xf51 0x25 0xf4a 0x27 0xf43 0x28 0xf3b 0x29 0xf31 0x2a 0xf26 0x2b 0xf1d 0x2d 0xf15 0x2e 0xf0e 0x2f 0xf08 0x30 0xf02 0x31 0xefd 0x33 0xef8 0x34 0xef4 0x35 0xef0 0x36 0xeec 0x39 0xee5 0x3b 0xedd 0x3d 0xed8 0x40 0xed2 0x41 0xed0 0x42 0xecd 0x43 0xeca 0x45 0xec7 0x46 0xec3 0x47 0xebc 0x48 0xeb3 0x49 0xeab 0x4b 0xea5 0x4c 0xe9f 0x4d 0xe99 0x4e 0xe95 0x4f 0xe90 0x51 0xe8d 0x52 0xe89 0x53 0xe84 0x54 0xe7e 0x55 0xe77 0x57 0xe71 0x58 0xe68 0x59 0xe60 0x5a 0xe5c 0x5b 0xe58 0x5d 0xe54 0x5e 0xe4e 0x5f 0xe42 0x60 0xe20 0x61 0xdee 0x63 0xdad 0x64 0xd56>;
			r_profile_t1_500cycle_1 = <0xb1 0x1060 0xaf 0x105b 0xb0 0x104d 0xb1 0x1041 0xb2 0x1036 0xb3 0x102b 0xb4 0x1020 0xb5 0x1016 0xb6 0x100b 0xb7 0x1002 0xb9 0xff8 0xba 0xfee 0xbb 0xfe5 0xbc 0xfdc 0xbd 0xfd3 0xbe 0xfca 0xbf 0xfc1 0xc0 0xfb9 0xc1 0xfb0 0xc3 0xfa9 0xc4 0xfa0 0xc4 0xf99 0xc6 0xf91 0xc7 0xf8a 0xc8 0xf83 0xc8 0xf7c 0xc9 0xf75 0xca 0xf6e 0xca 0xf67 0xca 0xf5f 0xca 0xf58 0xc9 0xf51 0xc8 0xf49 0xc6 0xf40 0xc4 0xf38 0xc1 0xf2f 0xbf 0xf26 0xbd 0xf1e 0xbb 0xf17 0xbb 0xf10 0xba 0xf09 0xba 0xf03 0xba 0xefe 0xb9 0xef9 0xba 0xef5 0xba 0xef0 0xbb 0xeed 0xbb 0xee9 0xbc 0xee6 0xbd 0xee2 0xbd 0xedf 0xbf 0xed9 0xc0 0xed5 0xc1 0xed2 0xc1 0xece 0xc2 0xeca 0xc2 0xec8 0xc2 0xec3 0xc1 0xec0 0xc0 0xebb 0xbe 0xeb6 0xbf 0xeb1 0xbf 0xead 0xc0 0xea9 0xc0 0xea4 0xc1 0xe9e 0xc1 0xe98 0xc2 0xe91 0xc3 0xe8a 0xc3 0xe82 0xc2 0xe78 0xc2 0xe71 0xc5 0xe6b 0xca 0xe66 0xd0 0xe5f 0xd9 0xe54 0xde 0xe40 0xdb 0xe13 0xe0 0xdd3 0xed 0xd7d>;
			r_profile_t1_5_500cycle_1 = <0x7b 0x105c 0x86 0x104e 0x87 0x1042 0x87 0x1037 0x88 0x102b 0x89 0x1021 0x89 0x1016 0x8b 0x100c 0x8b 0x1002 0x8d 0xff9 0x8d 0xfef 0x8e 0xfe5 0x8e 0xfdc 0x90 0xfd3 0x90 0xfca 0x91 0xfc2 0x93 0xfba 0x93 0xfb1 0x95 0xfa9 0x95 0xfa1 0x96 0xf9a 0x97 0xf93 0x98 0xf8b 0x99 0xf84 0x9a 0xf7d 0x9a 0xf76 0x9c 0xf70 0x9c 0xf69 0x9d 0xf62 0x9e 0xf5c 0x9e 0xf55 0x9e 0xf4e 0x9d 0xf46 0x9b 0xf3d 0x97 0xf33 0x94 0xf2a 0x91 0xf20 0x90 0xf18 0x90 0xf11 0x8f 0xf0b 0x8f 0xf05 0x8f 0xf00 0x8f 0xefb 0x8f 0xef6 0x8f 0xef2 0x8f 0xeee 0x90 0xeeb 0x90 0xee7 0x91 0xee4 0x92 0xee1 0x92 0xede 0x93 0xedb 0x94 0xed6 0x95 0xed1 0x96 0xecf 0x96 0xecb 0x95 0xec6 0x93 0xec2 0x92 0xebd 0x90 0xeb7 0x8f 0xeb1 0x8f 0xead 0x91 0xea9 0x91 0xea5 0x92 0xea1 0x92 0xe9c 0x92 0xe96 0x92 0xe8f 0x93 0xe89 0x94 0xe80 0x92 0xe77 0x93 0xe70 0x94 0xe6c 0x96 0xe67 0x9b 0xe61 0xa0 0xe58 0xa0 0xe42 0x9c 0xe14 0x9f 0xdd5 0xa5 0xd80>;
			r_profile_t2_500cycle_1 = <0x6d 0x1054 0x6d 0x1044 0x6d 0x1036 0x6d 0x1029 0x6e 0x101d 0x6f 0x1012 0x6f 0x1007 0x6e 0xffc 0x70 0xff2 0x70 0xfe8 0x71 0xfdf 0x70 0xfd5 0x72 0xfcc 0x71 0xfc3 0x73 0xfbb 0x72 0xfb1 0x74 0xfa9 0x74 0xfa0 0x75 0xf99 0x75 0xf90 0x77 0xf89 0x78 0xf82 0x79 0xf7b 0x7a 0xf74 0x7a 0xf6c 0x7b 0xf66 0x7b 0xf5e 0x7d 0xf58 0x7d 0xf51 0x7d 0xf4b 0x7e 0xf44 0x7e 0xf3e 0x7e 0xf37 0x7e 0xf30 0x7d 0xf28 0x79 0xf1f 0x77 0xf15 0x75 0xf0c 0x73 0xf04 0x75 0xeff 0x74 0xef8 0x73 0xef3 0x73 0xeed 0x72 0xee8 0x73 0xee4 0x72 0xee0 0x73 0xedc 0x73 0xed5 0x74 0xed1 0x75 0xecb 0x75 0xec6 0x77 0xec1 0x77 0xebe 0x79 0xebc 0x79 0xeba 0x78 0xeb6 0x76 0xeb2 0x74 0xead 0x72 0xea6 0x72 0xea0 0x71 0xe9b 0x72 0xe96 0x72 0xe92 0x72 0xe8e 0x73 0xe8a 0x74 0xe85 0x73 0xe80 0x74 0xe7a 0x74 0xe73 0x74 0xe6c 0x73 0xe62 0x74 0xe5c 0x76 0xe58 0x76 0xe53 0x78 0xe4e 0x7c 0xe45 0x7f 0xe33 0x78 0xe09 0x7b 0xdcf 0x80 0xd82>;
			r_profile_t3_500cycle_1 = <0x61 0x1057 0x61 0x104a 0x61 0x103d 0x61 0x1032 0x61 0x1027 0x62 0x101c 0x62 0x1012 0x62 0x1007 0x62 0xffe 0x63 0xff4 0x63 0xfea 0x63 0xfe1 0x63 0xfd8 0x64 0xfcf 0x64 0xfc6 0x65 0xfbe 0x65 0xfb5 0x66 0xfad 0x66 0xfa5 0x66 0xf9d 0x67 0xf95 0x67 0xf8e 0x68 0xf86 0x6a 0xf7f 0x69 0xf78 0x6a 0xf71 0x6c 0xf6b 0x6c 0xf64 0x6c 0xf5e 0x6d 0xf57 0x6e 0xf51 0x6f 0xf4a 0x6f 0xf43 0x6e 0xf3b 0x6b 0xf31 0x68 0xf26 0x67 0xf1d 0x67 0xf15 0x67 0xf0e 0x66 0xf08 0x66 0xf02 0x67 0xefd 0x67 0xef8 0x67 0xef4 0x67 0xef0 0x67 0xeec 0x68 0xee5 0x68 0xedd 0x6a 0xed8 0x6b 0xed2 0x6c 0xed0 0x6d 0xecd 0x6c 0xeca 0x6d 0xec7 0x6c 0xec3 0x69 0xebc 0x67 0xeb3 0x67 0xeab 0x68 0xea5 0x67 0xe9f 0x67 0xe99 0x68 0xe95 0x68 0xe90 0x68 0xe8d 0x68 0xe89 0x69 0xe84 0x69 0xe7e 0x69 0xe77 0x69 0xe71 0x69 0xe68 0x69 0xe60 0x69 0xe5c 0x6a 0xe58 0x6b 0xe54 0x6d 0xe4e 0x6f 0xe42 0x6c 0xe20 0x6d 0xdee 0x71 0xdad 0x76 0xd56>;
		};

		BAT_NOTIFY {
			compatible = "mediatek,bat_notify";
		};

		bat_comm {
			compatible = "mediatek,battery";
			stop_charging_in_takling = <0x01>;
			talking_recharge_voltage = <0xed8>;
			talking_sync_time = <0x3c>;
			mtk_temperature_recharge_support = <0x01>;
			max_charge_temperature = <0x3c>;
			max_charge_temperature_minus_x_degree = <0x3c>;
			min_charge_temperature = <0x00>;
			min_charge_temperature_plus_x_degree = <0x06>;
			err_charge_temperature = <0xff>;
			v_pre2cc_thres = <0xd48>;
			v_cc2topoff_thres = <0xfd2>;
			recharging_voltage = <0x100e>;
			charging_full_current = <0x96>;
			config_usb_if = <0x00>;
			usb_charger_current_suspend = <0x00>;
			usb_charger_current_unconfigured = <0x1b58>;
			usb_charger_current_configured = <0xc350>;
			usb_charger_current = <0xc350>;
			ac_charger_current = <0x1d4c0>;
			non_std_ac_charger_current = <0x1d4c0>;
			charging_host_charger_current = <0xc350>;
			apple_0_5a_charger_current = <0xc350>;
			apple_1_0a_charger_current = <0x186a0>;
			apple_2_1a_charger_current = <0x33450>;
			bat_low_temp_protect_enable = <0x00>;
			v_charger_enable = <0x00>;
			v_charger_max = <0x1964>;
			v_charger_min = <0x1130>;
			onehundred_percent_tracking_time = <0x0a>;
			npercent_tracking_time = <0x14>;
			sync_to_real_tracking_time = <0x3c>;
			v_0percent_tracking = <0xd48>;
			system_off_voltage = <0xd48>;
			high_battery_voltage_support = <0x00>;
			ac_charger_input_current = <0x186a0>;
			non_std_ac_charger_input_current = <0x186a0>;
			mtk_jeita_standard_support = <0x01>;
			cust_soc_jeita_sync_time = <0x1e>;
			jeita_recharge_voltage = <0x100e>;
			jeita_temp_above_pos_60_cv_voltage = <0x3e8fa0>;
			jeita_temp_pos_45_to_pos_60_cv_voltage = <0x3e8fa0>;
			jeita_temp_pos_10_to_pos_45_cv_voltage = <0x401640>;
			jeita_temp_pos_0_to_pos_10_cv_voltage = <0x401640>;
			jeita_temp_neg_10_to_pos_0_cv_voltage = <0x401640>;
			jeita_temp_below_neg_10_cv_voltage = <0x401640>;
			jeita_neg_10_to_pos_0_full_current = <0x78>;
			jeita_temp_pos_45_to_pos_60_recharge_voltage = <0xfa0>;
			jeita_temp_pos_10_to_pos_45_recharge_voltage = <0x1004>;
			jeita_temp_pos_0_to_pos_10_recharge_voltage = <0x1004>;
			jeita_temp_neg_10_to_pos_0_recharge_voltage = <0x1004>;
			jeita_temp_pos_45_to_pos_60_cc2topoff_threshold = <0xfd2>;
			jeita_temp_pos_10_to_pos_45_cc2topoff_threshold = <0xfd2>;
			jeita_temp_pos_0_to_pos_10_cc2topoff_threshold = <0xfd2>;
			jeita_temp_neg_10_to_pos_0_cc2topoff_threshold = <0xfd2>;
		};

		flashlight@ {
			compatible = "mediatek,camera_flashlight";
		};

		isp_pipemgr {
			compatible = "mediatek,mt8163-isp_pipemgr";
		};

		isp_sysram {
			compatible = "mediatek,mt8163-isp_sysram";
		};

		mtee {
			compatible = "mediatek,mtee";
		};
	};

	lcm {
		compatible = "mediatek,lcm";
		pinctrl-names = "default\0lcm_pwr_high\0lcm_pwr_low\0lcm_rst_high\0lcm_rst_low";
		pinctrl-0 = <0x57>;
		pinctrl-1 = <0x6b>;
		pinctrl-2 = <0x6c>;
		pinctrl-3 = <0x6d>;
		pinctrl-4 = <0x6e>;
		reg-lcm-supply = <0x6f>;
	};

	memory@00000000 {
		device_type = "memory";
		reg = <0x00 0x40000000 0x00 0x20000000>;
	};

	cust_gsensor@0 {
		compatible = "mediatek,bma253";
		i2c_num = <0x02>;
		i2c_addr = <0x18>;
		direction = <0x04>;
		power_id = <0xffff>;
		power_vol = <0x00>;
		firlen = <0x10>;
		is_batch_supported = <0x00>;
	};

	cust_gyroscope@0 {
		compatible = "mediatek,lsm6ds3gy";
		i2c_num = <0x02>;
		i2c_addr = <0x6a>;
		direction = <0x00>;
		power_id = <0xffff>;
		power_vol = <0x00>;
		firlen = <0x00>;
		is_batch_supported = <0x00>;
	};

	chosen {
		bootargs = "console=ttyS0,921600n1 root=/dev/ram initrd=0x44000200,0x200000";
	};

	mtcpufreq {
		compatible = "mediatek,mt8163-cpufreq";
		reg-ext-vproc-supply = <0x70>;
	};

	hall_sensors {
		compatible = "rohm,hall-bu520";
		interrupt-parent = <0x09>;
		interrupts = <0x13 0x08>;
		int-gpio = <0x09 0x33 0x00>;
		sensor-name = "hall_sensor_1";
		sensor-num = <0x01>;
	};

	cust_alsps@0 {
		compatible = "mediatek,jsa1214";
		i2c_num = <0x02>;
		i2c_addr = <0x44>;
		polling_mode_ps = <0x00>;
		polling_mode_als = <0x01>;
		power_id = <0xffff>;
		power_vol = <0x00>;
		als_level = <0x00 0x101 0x27d 0x403 0x8f9 0x15d4 0x1a4a 0x2c25 0x4fe1 0x64a8 0x7992 0xb1f0 0xe251 0xe251 0xe251>;
		als_value = <0x00 0x84 0x130 0x1f6 0x3ec 0x7d3 0xbbe 0x138e 0x1f44 0x2710 0x2ee0 0x3e80 0x4e20 0x4e20 0x4e20 0x4e20>;
		ps_threshold_high = <0x46>;
		ps_threshold_low = <0x28>;
		is_batch_supported_ps = <0x01>;
	};

	thermistor@0 {
		compatible = "amazon,virtual_sensor_thermistor";
		thermistor,offset = <0x2328>;
		thermistor,offset.sign = "plus";
		thermistor,alpha = <0x0a>;
		thermistor,weight = <0xc8>;
		aux_channel_num = <0x00>;
	};

	thermistor@1 {
		compatible = "amazon,virtual_sensor_thermistor";
		thermistor,offset = <0x2328>;
		thermistor,offset.sign = "plus";
		thermistor,alpha = <0x0a>;
		thermistor,weight = <0xc8>;
		aux_channel_num = <0x01>;
	};

	thermistor@2 {
		compatible = "amazon,virtual_sensor_thermistor";
		thermistor,offset = <0x2710>;
		thermistor,offset.sign = "plus";
		thermistor,alpha = <0x0a>;
		thermistor,weight = <0xc8>;
		aux_channel_num = <0x02>;
	};
};
